VERSION "2027-draft-2026-10-23"

NS_ :

BS_:

BU_: BPS DEI External LVC MIKA MPPTInterface PDU Pedals VCU
VAL_TABLE_ EnableDisable 1 "Enabled" 0 "Disabled" ;
VAL_TABLE_ OnOff 1 "On" 0 "Off" ;
VAL_TABLE_ FaultState 1 "Fault" 0 "OK" ;
VAL_TABLE_ WarningState 1 "Warning" 0 "NoWarning" ;
VAL_TABLE_ DeviceStatus 2 "Waiting" 1 "Fault" 0 "OK" ;
VAL_TABLE_ Permission 1 "Allowed" 0 "NotAllowed" ;
VAL_TABLE_ Connection 1 "Connected" 0 "Disconnected" ;
VAL_TABLE_ Pressed 1 "Pressed" 0 "NotPressed" ;
VAL_TABLE_ Validity 1 "Valid" 0 "Invalid" ;
VAL_TABLE_ Watchdog 1 "TimedOut" 0 "Alive" ;
VAL_TABLE_ NormalAdvanced 1 "Advanced" 0 "Normal" ;
VAL_TABLE_ MotorCommandSource 1 "External" 0 "VCU" ;
VAL_TABLE_ Gear 3 "Invalid" 2 "Reverse" 1 "Forward" 0 "Neutral" ;
VAL_TABLE_ BPSFaultSummary 5 "SMBFault" 4 "PrechargeFault" 3 "ContactorRelayFault" 2 "EmergencyStop" 1 "SetpointFault" 0 "OK" ;
VAL_TABLE_ VCUState 7 "VehicleNotReady" 6 "Disabled" 5 "CruiseControl" 4 "Regen" 3 "ReverseDrive" 2 "NeutralDrive" 1 "ForwardDrive" 0 "Init" ;
VAL_TABLE_ ChargeState 2 "Charging" 1 "Standby" 0 "Disabled" ;
VAL_TABLE_ EVSEState 5 "F_EVSEFault" 4 "E_Fault" 3 "D_VentilationRequired" 2 "C_ChargingReady" 1 "B_Connected" 0 "A_Disconnected" ;
VAL_TABLE_ GPSAntennaState 3 "Unknown" 2 "ShortCircuit" 1 "OpenCircuit" 0 "OK" ;
VAL_TABLE_ GPSFix 2 "Fix3D" 1 "Fix2D" 0 "NoFix" ;
VAL_TABLE_ CellularTechnology 4 "Other" 3 "NB_IoT" 2 "LTE_M" 1 "LTE" 0 "None" ;
VAL_TABLE_ TPEEControlMode 2 "ConstantInputVoltage" 1 "PerturbAndObserve" 0 "Disabled" ;
VAL_TABLE_ TPEEOperatingMode 7 "Fault" 6 "MinimumInputVoltage" 5 "TemperatureDerating" 4 "ConstantOutputCurrent" 3 "ConstantOutputVoltage" 2 "MinimumInputCurrent" 1 "ConstantInputCurrent" 0 "ConstantInputVoltage" ;
VAL_TABLE_ TPEEFault 8 "Fault" 7 "PhaseOverCurrent" 6 "InputUnderCurrent" 5 "InputOverCurrent" 4 "OutputOverCurrent" 3 "OutputOverVoltage" 2 "InputOverVoltage" 1 "ConfigurationError" 0 "OK" ;
VAL_TABLE_ LWSCalibration 1 "Calibrated" 0 "NotCalibrated" ;
VAL_TABLE_ LWSTrim 1 "Trimmed" 0 "NotTrimmed" ;
VAL_TABLE_ LWSCommand 5 "ResetCalibration" 3 "SetAngleZero" ;
VAL_TABLE_ ElconControl 1 "Disable" 0 "Charge" ;
VAL_TABLE_ ElconMuxPage 5 "Page5" 4 "Page4" 3 "Page3" 2 "Page2" 1 "Page1" ;

BO_ 81 BPSCommand: 12 External
 SG_ Mode : 0|1@1+ (1,0) [0.0|1.0] "" Vector__XXX
 SG_ MPPTChargeScheme : 1|1@1+ (1,0) [0.0|1.0] "" Vector__XXX
 SG_ VoltageOverrideMask : 2|32@1+ (1,0) [0.0|4294967295.0] "" Vector__XXX
 SG_ TemperatureOverrideMask : 34|32@1+ (1,0) [0.0|4294967295.0] "" Vector__XXX

BO_ 82 PDUCommand: 1 External
 SG_ ChannelIndex : 0|4@1+ (1,0) [0|13] "" Vector__XXX
 SG_ Enable : 4|1@1+ (1,0) [0.0|1.0] "" Vector__XXX

BO_ 83 MotorControllerCommand: 1 External
 SG_ CommandSource : 0|1@1+ (1,0) [0.0|1.0] "" Vector__XXX

BO_ 84 SweepMPPTs: 0 External

BO_ 96 BPSStatus: 16 BPS
 SG_ FaultSummary : 0|3@1+ (1,0) [0.0|7.0] "" Vector__XXX
 SG_ FaultOverTemperature : 3|1@1+ (1,0) [0.0|1.0] "" Vector__XXX
 SG_ FaultOverVoltage : 4|1@1+ (1,0) [0.0|1.0] "" Vector__XXX
 SG_ FaultUnderVoltage : 5|1@1+ (1,0) [0.0|1.0] "" Vector__XXX
 SG_ FaultChargeOverCurrent : 6|1@1+ (1,0) [0.0|1.0] "" Vector__XXX
 SG_ FaultDischargeOverCurrent : 7|1@1+ (1,0) [0.0|1.0] "" Vector__XXX
 SG_ FaultHVPositiveContactorMismatch : 8|1@1+ (1,0) [0.0|1.0] "" Vector__XXX
 SG_ FaultMotorContactorMismatch : 9|1@1+ (1,0) [0.0|1.0] "" Vector__XXX
 SG_ FaultHVNegativeContactorMismatch : 10|1@1+ (1,0) [0.0|1.0] "" Vector__XXX
 SG_ FaultMainPrechargeRelayMismatch : 11|1@1+ (1,0) [0.0|1.0] "" Vector__XXX
 SG_ FaultMotorPrechargeRelayMismatch : 12|1@1+ (1,0) [0.0|1.0] "" Vector__XXX
 SG_ FaultDriverEstop : 13|1@1+ (1,0) [0.0|1.0] "" Vector__XXX
 SG_ FaultExternalEstop : 14|1@1+ (1,0) [0.0|1.0] "" Vector__XXX
 SG_ FaultBatteryEstop : 15|1@1+ (1,0) [0.0|1.0] "" Vector__XXX
 SG_ FaultChargerEstop : 16|1@1+ (1,0) [0.0|1.0] "" Vector__XXX
 SG_ FaultMainPrechargeTimeout : 17|1@1+ (1,0) [0.0|1.0] "" Vector__XXX
 SG_ FaultMotorPrechargeTimeout : 18|1@1+ (1,0) [0.0|1.0] "" Vector__XXX
 SG_ FaultMainVoltage : 19|1@1+ (1,0) [0.0|1.0] "" Vector__XXX
 SG_ FaultMotorVoltage : 20|1@1+ (1,0) [0.0|1.0] "" Vector__XXX
 SG_ FaultMainPrechargeVoltage : 21|1@1+ (1,0) [0.0|1.0] "" Vector__XXX
 SG_ FaultMotorPrechargeVoltage : 22|1@1+ (1,0) [0.0|1.0] "" Vector__XXX
 SG_ WarningSMBCommunication : 24|1@1+ (1,0) [0.0|1.0] "" Vector__XXX
 SG_ WarningUnderVoltage : 25|1@1+ (1,0) [0.0|1.0] "" Vector__XXX
 SG_ WarningOverVoltage : 26|1@1+ (1,0) [0.0|1.0] "" Vector__XXX
 SG_ WarningChargeOverTemperature : 27|1@1+ (1,0) [0.0|1.0] "" Vector__XXX
 SG_ WarningDischargeOverTemperature : 28|1@1+ (1,0) [0.0|1.0] "" Vector__XXX
 SG_ WarningBatteryFan1 : 29|1@1+ (1,0) [0.0|1.0] "" Vector__XXX
 SG_ WarningBatteryFan2 : 30|1@1+ (1,0) [0.0|1.0] "" Vector__XXX
 SG_ WarningBPSFan : 31|1@1+ (1,0) [0.0|1.0] "" Vector__XXX
 SG_ Status : 32|2@1+ (1,0) [0.0|3.0] "" Vector__XXX
 SG_ DriveOK : 34|1@1+ (1,0) [0.0|1.0] "" Vector__XXX
 SG_ ChargeOK : 35|1@1+ (1,0) [0.0|1.0] "" Vector__XXX
 SG_ MPPTSetMode : 36|2@1+ (1,0) [0.0|3.0] "" Vector__XXX
 SG_ ElconChargeOK : 38|1@1+ (1,0) [0.0|1.0] "" Vector__XXX
 SG_ RegenChargeOK : 39|1@1+ (1,0) [0.0|1.0] "" Vector__XXX
 SG_ HVPositiveContactor : 40|1@1+ (1,0) [0.0|1.0] "" Vector__XXX
 SG_ MotorContactor : 41|1@1+ (1,0) [0.0|1.0] "" Vector__XXX
 SG_ HVNegativeContactor : 42|1@1+ (1,0) [0.0|1.0] "" Vector__XXX
 SG_ MainPrechargeRelay : 43|1@1+ (1,0) [0.0|1.0] "" Vector__XXX
 SG_ MotorPrechargeRelay : 44|1@1+ (1,0) [0.0|1.0] "" Vector__XXX
 SG_ MPPTVoltageLimit : 48|16@1+ (0.05,0) [0|175] "V" Vector__XXX
 SG_ MPPTCurrentLimit : 64|16@1+ (0.01,0) [0|16.38] "A" Vector__XXX
 SG_ BatteryFanTach1 : 80|12@1+ (5,0) [0.0|20475.0] "rpm" Vector__XXX
 SG_ BatteryFanTach2 : 92|12@1+ (5,0) [0.0|20475.0] "rpm" Vector__XXX
 SG_ BPSFanTach : 104|12@1+ (5,0) [0.0|20475.0] "rpm" Vector__XXX

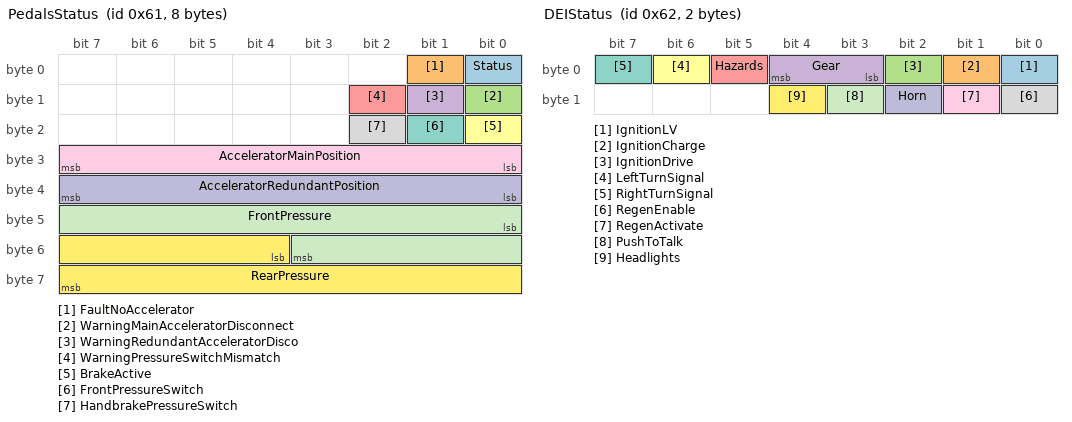
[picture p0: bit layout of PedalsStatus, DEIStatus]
BO_ 97 PedalsStatus: 8 Pedals
 SG_ Status : 0|1@1+ (1,0) [0.0|1.0] "" Vector__XXX
 SG_ FaultNoAccelerator : 1|1@1+ (1,0) [0.0|1.0] "" Vector__XXX
 SG_ WarningMainAcceleratorDisconnect : 8|1@1+ (1,0) [0.0|1.0] "" Vector__XXX
 SG_ WarningRedundantAcceleratorDisco : 9|1@1+ (1,0) [0.0|1.0] "" Vector__XXX
 SG_ WarningPressureSwitchMismatch : 10|1@1+ (1,0) [0.0|1.0] "" Vector__XXX
 SG_ BrakeActive : 16|1@1+ (1,0) [0.0|1.0] "" Vector__XXX
 SG_ FrontPressureSwitch : 17|1@1+ (1,0) [0.0|1.0] "" Vector__XXX
 SG_ HandbrakePressureSwitch : 18|1@1+ (1,0) [0.0|1.0] "" Vector__XXX
 SG_ AcceleratorMainPosition : 24|8@1+ (0.39215686274509803,0) [0|100] "%" Vector__XXX
 SG_ AcceleratorRedundantPosition : 32|8@1+ (0.39215686274509803,0) [0|100] "%" Vector__XXX
 SG_ FrontPressure : 40|12@1+ (1,0) [0|3000] "PSI" Vector__XXX
 SG_ RearPressure : 52|12@1+ (1,0) [0|3000] "PSI" Vector__XXX

BO_ 98 DEIStatus: 2 DEI
 SG_ IgnitionLV : 0|1@1+ (1,0) [0.0|1.0] "" Vector__XXX
 SG_ IgnitionCharge : 1|1@1+ (1,0) [0.0|1.0] "" Vector__XXX
 SG_ IgnitionDrive : 2|1@1+ (1,0) [0.0|1.0] "" Vector__XXX
 SG_ Gear : 3|2@1+ (1,0) [0.0|3.0] "" Vector__XXX
 SG_ Hazards : 5|1@1+ (1,0) [0.0|1.0] "" Vector__XXX
 SG_ LeftTurnSignal : 6|1@1+ (1,0) [0.0|1.0] "" Vector__XXX
 SG_ RightTurnSignal : 7|1@1+ (1,0) [0.0|1.0] "" Vector__XXX
 SG_ RegenEnable : 8|1@1+ (1,0) [0.0|1.0] "" Vector__XXX
 SG_ RegenActivate : 9|1@1+ (1,0) [0.0|1.0] "" Vector__XXX
 SG_ Horn : 10|1@1+ (1,0) [0.0|1.0] "" Vector__XXX
 SG_ PushToTalk : 11|1@1+ (1,0) [0.0|1.0] "" Vector__XXX
 SG_ Headlights : 12|1@1+ (1,0) [0.0|1.0] "" Vector__XXX

BO_ 99 VCUStatus: 7 VCU
 SG_ Status : 0|1@1+ (1,0) [0.0|1.0] "" Vector__XXX
 SG_ FaultMotor : 1|1@1+ (1,0) [0.0|1.0] "" Vector__XXX
 SG_ FaultBPS : 2|1@1+ (1,0) [0.0|1.0] "" Vector__XXX
 SG_ FaultPedals : 3|1@1+ (1,0) [0.0|1.0] "" Vector__XXX
 SG_ FaultMotorControllerWatchdog : 4|1@1+ (1,0) [0.0|1.0] "" Vector__XXX
 SG_ FaultBPSWatchdog : 5|1@1+ (1,0) [0.0|1.0] "" Vector__XXX
 SG_ FaultDriverInputWatchdog : 6|1@1+ (1,0) [0.0|1.0] "" Vector__XXX
 SG_ FaultPedalsWatchdog : 7|1@1+ (1,0) [0.0|1.0] "" Vector__XXX
 SG_ WarningTipping : 8|1@1+ (1,0) [0.0|1.0] "" Vector__XXX
 SG_ WarningDirectionChangeLockout : 9|1@1+ (1,0) [0.0|1.0] "" Vector__XXX
 SG_ WarningMotorControllerFan : 10|1@1+ (1,0) [0.0|1.0] "" Vector__XXX
 SG_ WarningMotorFan : 11|1@1+ (1,0) [0.0|1.0] "" Vector__XXX
 SG_ RegenEnabled : 16|1@1+ (1,0) [0.0|1.0] "" Vector__XXX
 SG_ State : 17|3@1+ (1,0) [0.0|7.0] "" Vector__XXX
 SG_ FSMBrake : 20|1@1+ (1,0) [0.0|1.0] "" Vector__XXX
 SG_ FSMBPSDriveOK : 21|1@1+ (1,0) [0.0|1.0] "" Vector__XXX
 SG_ FSMBPSRegenOK : 22|1@1+ (1,0) [0.0|1.0] "" Vector__XXX
 SG_ FSMDriverRegenEnable : 23|1@1+ (1,0) [0.0|1.0] "" Vector__XXX
 SG_ FSMDriverRegenRequest : 24|1@1+ (1,0) [0.0|1.0] "" Vector__XXX
 SG_ FSMGear : 25|2@1+ (1,0) [0.0|3.0] "" Vector__XXX
 SG_ MotorCommandSource : 27|1@1+ (1,0) [0.0|1.0] "" Vector__XXX
 SG_ MotorControllerFanTach : 32|12@1+ (5,0) [0.0|20475.0] "rpm" Vector__XXX
 SG_ MotorFanTach : 44|12@1+ (5,0) [0.0|20475.0] "rpm" Vector__XXX

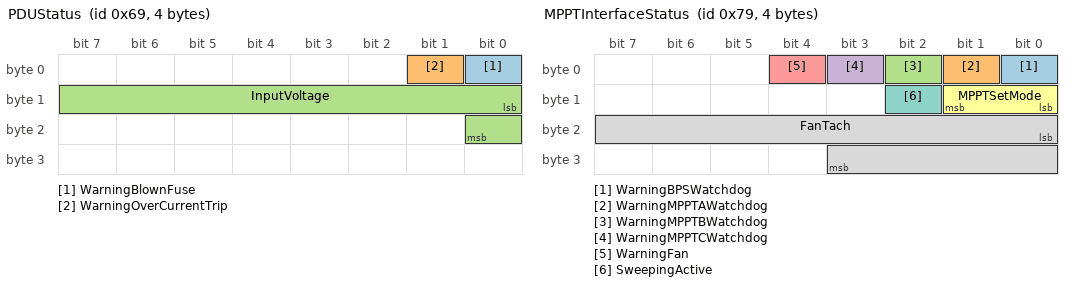
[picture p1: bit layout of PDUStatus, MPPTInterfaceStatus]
BO_ 105 PDUStatus: 4 PDU
 SG_ WarningBlownFuse : 0|1@1+ (1,0) [0.0|1.0] "" Vector__XXX
 SG_ WarningOverCurrentTrip : 1|1@1+ (1,0) [0.0|1.0] "" Vector__XXX
 SG_ InputVoltage : 8|9@1+ (0.05,0) [5|20] "V" Vector__XXX

BO_ 106 LVCStatus: 12 LVC
 SG_ WarningNoDCDCOutput : 0|1@1+ (1,0) [0.0|1.0] "" Vector__XXX
 SG_ WarningBPSOverCurrent : 1|1@1+ (1,0) [0.0|1.0] "" Vector__XXX
 SG_ WarningBPSBlownFuse : 2|1@1+ (1,0) [0.0|1.0] "" Vector__XXX
 SG_ DCDCEnabled : 8|1@1+ (1,0) [0.0|1.0] "" Vector__XXX
 SG_ DCDCVoltage : 16|9@1+ (0.05,0) [5|20] "V" Vector__XXX
 SG_ DCDCCurrent : 25|11@1+ (0.01,0) [0|20] "A" Vector__XXX
 SG_ LVBVoltage : 36|9@1+ (0.05,0) [5|20] "V" Vector__XXX
 SG_ LVBCurrent : 45|11@1+ (0.01,0) [0|20] "A" Vector__XXX
 SG_ PowerSupplyVoltage : 56|9@1+ (0.05,0) [5|20] "V" Vector__XXX
 SG_ TotalOutputCurrent : 65|11@1+ (0.01,0) [0|20] "A" Vector__XXX
 SG_ BPSLVCurrent : 76|11@1+ (0.01,0) [0|20] "A" Vector__XXX

BO_ 112 BPSPackData: 12 BPS
 SG_ CellSumVoltage : 0|12@1+ (0.05,0) [0.0|204.75] "V" Vector__XXX
 SG_ MainBatteryVoltage : 12|12@1+ (0.05,0) [0.0|204.75] "V" Vector__XXX
 SG_ MotorBatteryVoltage : 24|12@1+ (0.05,0) [0.0|204.75] "V" Vector__XXX
 SG_ MainVoltage : 36|12@1+ (0.05,0) [0.0|204.75] "V" Vector__XXX
 SG_ MotorVoltage : 48|12@1+ (0.05,0) [0.0|204.75] "V" Vector__XXX
 SG_ BatteryCurrent : 60|14@1+ (0.01,-50) [-50.0|113.83] "A" Vector__XXX

BO_ 113 BPSVoltageData: 64 BPS
 SG_ CellVoltage01 : 0|12@1+ (1,2000) [2000.0|6095.0] "mV" Vector__XXX
 SG_ CellVoltage02 : 12|12@1+ (1,2000) [2000.0|6095.0] "mV" Vector__XXX
 SG_ CellVoltage03 : 24|12@1+ (1,2000) [2000.0|6095.0] "mV" Vector__XXX
 SG_ CellVoltage04 : 36|12@1+ (1,2000) [2000.0|6095.0] "mV" Vector__XXX
 SG_ CellVoltage05 : 48|12@1+ (1,2000) [2000.0|6095.0] "mV" Vector__XXX
 SG_ CellVoltage06 : 60|12@1+ (1,2000) [2000.0|6095.0] "mV" Vector__XXX
 SG_ CellVoltage07 : 72|12@1+ (1,2000) [2000.0|6095.0] "mV" Vector__XXX
 SG_ CellVoltage08 : 84|12@1+ (1,2000) [2000.0|6095.0] "mV" Vector__XXX
 SG_ CellVoltage09 : 96|12@1+ (1,2000) [2000.0|6095.0] "mV" Vector__XXX
 SG_ CellVoltage10 : 108|12@1+ (1,2000) [2000.0|6095.0] "mV" Vector__XXX
 SG_ CellVoltage11 : 120|12@1+ (1,2000) [2000.0|6095.0] "mV" Vector__XXX
 SG_ CellVoltage12 : 132|12@1+ (1,2000) [2000.0|6095.0] "mV" Vector__XXX
 SG_ CellVoltage13 : 144|12@1+ (1,2000) [2000.0|6095.0] "mV" Vector__XXX
 SG_ CellVoltage14 : 156|12@1+ (1,2000) [2000.0|6095.0] "mV" Vector__XXX
 SG_ CellVoltage15 : 168|12@1+ (1,2000) [2000.0|6095.0] "mV" Vector__XXX
 SG_ CellVoltage16 : 180|12@1+ (1,2000) [2000.0|6095.0] "mV" Vector__XXX
 SG_ CellVoltage17 : 192|12@1+ (1,2000) [2000.0|6095.0] "mV" Vector__XXX
 SG_ CellVoltage18 : 204|12@1+ (1,2000) [2000.0|6095.0] "mV" Vector__XXX
 SG_ CellVoltage19 : 216|12@1+ (1,2000) [2000.0|6095.0] "mV" Vector__XXX
 SG_ CellVoltage20 : 228|12@1+ (1,2000) [2000.0|6095.0] "mV" Vector__XXX
 SG_ CellVoltage21 : 240|12@1+ (1,2000) [2000.0|6095.0] "mV" Vector__XXX
 SG_ CellVoltage22 : 252|12@1+ (1,2000) [2000.0|6095.0] "mV" Vector__XXX
 SG_ CellVoltage23 : 264|12@1+ (1,2000) [2000.0|6095.0] "mV" Vector__XXX
 SG_ CellVoltage24 : 276|12@1+ (1,2000) [2000.0|6095.0] "mV" Vector__XXX
 SG_ CellVoltage25 : 288|12@1+ (1,2000) [2000.0|6095.0] "mV" Vector__XXX
 SG_ CellVoltage26 : 300|12@1+ (1,2000) [2000.0|6095.0] "mV" Vector__XXX
 SG_ CellVoltage27 : 312|12@1+ (1,2000) [2000.0|6095.0] "mV" Vector__XXX
 SG_ CellVoltage28 : 324|12@1+ (1,2000) [2000.0|6095.0] "mV" Vector__XXX
 SG_ CellVoltage29 : 336|12@1+ (1,2000) [2000.0|6095.0] "mV" Vector__XXX
 SG_ CellVoltage30 : 348|12@1+ (1,2000) [2000.0|6095.0] "mV" Vector__XXX
 SG_ CellVoltage31 : 360|12@1+ (1,2000) [2000.0|6095.0] "mV" Vector__XXX
 SG_ CellVoltage32 : 372|12@1+ (1,2000) [2000.0|6095.0] "mV" Vector__XXX
 SG_ MinCellVoltage : 384|12@1+ (1,2000) [2000.0|6095.0] "mV" Vector__XXX
 SG_ MaxCellVoltage : 396|12@1+ (1,2000) [2000.0|6095.0] "mV" Vector__XXX

BO_ 114 BPSTemperatureData: 48 BPS
 SG_ CellTemperature01 : 0|11@1+ (0.05,0) [0.0|102.35] "degC" Vector__XXX
 SG_ CellTemperature02 : 11|11@1+ (0.05,0) [0.0|102.35] "degC" Vector__XXX
 SG_ CellTemperature03 : 22|11@1+ (0.05,0) [0.0|102.35] "degC" Vector__XXX
 SG_ CellTemperature04 : 33|11@1+ (0.05,0) [0.0|102.35] "degC" Vector__XXX
 SG_ CellTemperature05 : 44|11@1+ (0.05,0) [0.0|102.35] "degC" Vector__XXX
 SG_ CellTemperature06 : 55|11@1+ (0.05,0) [0.0|102.35] "degC" Vector__XXX
 SG_ CellTemperature07 : 66|11@1+ (0.05,0) [0.0|102.35] "degC" Vector__XXX
 SG_ CellTemperature08 : 77|11@1+ (0.05,0) [0.0|102.35] "degC" Vector__XXX
 SG_ CellTemperature09 : 88|11@1+ (0.05,0) [0.0|102.35] "degC" Vector__XXX
 SG_ CellTemperature10 : 99|11@1+ (0.05,0) [0.0|102.35] "degC" Vector__XXX
 SG_ CellTemperature11 : 110|11@1+ (0.05,0) [0.0|102.35] "degC" Vector__XXX
 SG_ CellTemperature12 : 121|11@1+ (0.05,0) [0.0|102.35] "degC" Vector__XXX
 SG_ CellTemperature13 : 132|11@1+ (0.05,0) [0.0|102.35] "degC" Vector__XXX
 SG_ CellTemperature14 : 143|11@1+ (0.05,0) [0.0|102.35] "degC" Vector__XXX
 SG_ CellTemperature15 : 154|11@1+ (0.05,0) [0.0|102.35] "degC" Vector__XXX
 SG_ CellTemperature16 : 165|11@1+ (0.05,0) [0.0|102.35] "degC" Vector__XXX
 SG_ CellTemperature17 : 176|11@1+ (0.05,0) [0.0|102.35] "degC" Vector__XXX
 SG_ CellTemperature18 : 187|11@1+ (0.05,0) [0.0|102.35] "degC" Vector__XXX
 SG_ CellTemperature19 : 198|11@1+ (0.05,0) [0.0|102.35] "degC" Vector__XXX
 SG_ CellTemperature20 : 209|11@1+ (0.05,0) [0.0|102.35] "degC" Vector__XXX
 SG_ CellTemperature21 : 220|11@1+ (0.05,0) [0.0|102.35] "degC" Vector__XXX
 SG_ CellTemperature22 : 231|11@1+ (0.05,0) [0.0|102.35] "degC" Vector__XXX
 SG_ CellTemperature23 : 242|11@1+ (0.05,0) [0.0|102.35] "degC" Vector__XXX
 SG_ CellTemperature24 : 253|11@1+ (0.05,0) [0.0|102.35] "degC" Vector__XXX
 SG_ CellTemperature25 : 264|11@1+ (0.05,0) [0.0|102.35] "degC" Vector__XXX
 SG_ CellTemperature26 : 275|11@1+ (0.05,0) [0.0|102.35] "degC" Vector__XXX
 SG_ CellTemperature27 : 286|11@1+ (0.05,0) [0.0|102.35] "degC" Vector__XXX
 SG_ CellTemperature28 : 297|11@1+ (0.05,0) [0.0|102.35] "degC" Vector__XXX
 SG_ CellTemperature29 : 308|11@1+ (0.05,0) [0.0|102.35] "degC" Vector__XXX
 SG_ CellTemperature30 : 319|11@1+ (0.05,0) [0.0|102.35] "degC" Vector__XXX
 SG_ CellTemperature31 : 330|11@1+ (0.05,0) [0.0|102.35] "degC" Vector__XXX
 SG_ CellTemperature32 : 341|11@1+ (0.05,0) [0.0|102.35] "degC" Vector__XXX
 SG_ MaxBatteryTemperature : 352|11@1+ (0.05,0) [0.0|102.35] "degC" Vector__XXX
 SG_ AverageBatteryTemperature : 363|11@1+ (0.05,0) [0.0|102.35] "degC" Vector__XXX

BO_ 115 SMDStatus: 0 BPS

BO_ 116 BPSCommandEcho: 12 BPS
 SG_ Mode : 0|1@1+ (1,0) [0.0|1.0] "" Vector__XXX
 SG_ MPPTChargeScheme : 1|1@1+ (1,0) [0.0|1.0] "" Vector__XXX
 SG_ VoltageOverrideMask : 2|32@1+ (1,0) [0.0|4294967295.0] "" Vector__XXX
 SG_ TemperatureOverrideMask : 34|32@1+ (1,0) [0.0|4294967295.0] "" Vector__XXX

BO_ 120 PDUData: 32 PDU
 SG_ ChannelBlownFuse1 : 0|1@1+ (1,0) [0.0|1.0] "" Vector__XXX
 SG_ ChannelOverCurrent1 : 1|1@1+ (1,0) [0.0|1.0] "" Vector__XXX
 SG_ ChannelBlownFuse2 : 2|1@1+ (1,0) [0.0|1.0] "" Vector__XXX
 SG_ ChannelOverCurrent2 : 3|1@1+ (1,0) [0.0|1.0] "" Vector__XXX
 SG_ ChannelBlownFuse3 : 4|1@1+ (1,0) [0.0|1.0] "" Vector__XXX
 SG_ ChannelOverCurrent3 : 5|1@1+ (1,0) [0.0|1.0] "" Vector__XXX
 SG_ ChannelBlownFuse4 : 6|1@1+ (1,0) [0.0|1.0] "" Vector__XXX
 SG_ ChannelOverCurrent4 : 7|1@1+ (1,0) [0.0|1.0] "" Vector__XXX
 SG_ ChannelBlownFuse5 : 8|1@1+ (1,0) [0.0|1.0] "" Vector__XXX
 SG_ ChannelOverCurrent5 : 9|1@1+ (1,0) [0.0|1.0] "" Vector__XXX
 SG_ ChannelBlownFuse6 : 10|1@1+ (1,0) [0.0|1.0] "" Vector__XXX
 SG_ ChannelOverCurrent6 : 11|1@1+ (1,0) [0.0|1.0] "" Vector__XXX
 SG_ ChannelBlownFuse7 : 12|1@1+ (1,0) [0.0|1.0] "" Vector__XXX
 SG_ ChannelOverCurrent7 : 13|1@1+ (1,0) [0.0|1.0] "" Vector__XXX
 SG_ ChannelBlownFuse8 : 14|1@1+ (1,0) [0.0|1.0] "" Vector__XXX
 SG_ ChannelOverCurrent8 : 15|1@1+ (1,0) [0.0|1.0] "" Vector__XXX
 SG_ ChannelBlownFuse9 : 16|1@1+ (1,0) [0.0|1.0] "" Vector__XXX
 SG_ ChannelOverCurrent9 : 17|1@1+ (1,0) [0.0|1.0] "" Vector__XXX
 SG_ ChannelBlownFuse10 : 18|1@1+ (1,0) [0.0|1.0] "" Vector__XXX
 SG_ ChannelOverCurrent10 : 19|1@1+ (1,0) [0.0|1.0] "" Vector__XXX
 SG_ ChannelBlownFuse11 : 20|1@1+ (1,0) [0.0|1.0] "" Vector__XXX
 SG_ ChannelOverCurrent11 : 21|1@1+ (1,0) [0.0|1.0] "" Vector__XXX
 SG_ ChannelBlownFuse12 : 22|1@1+ (1,0) [0.0|1.0] "" Vector__XXX
 SG_ ChannelOverCurrent12 : 23|1@1+ (1,0) [0.0|1.0] "" Vector__XXX
 SG_ ChannelBlownFuse13 : 24|1@1+ (1,0) [0.0|1.0] "" Vector__XXX
 SG_ ChannelOverCurrent13 : 25|1@1+ (1,0) [0.0|1.0] "" Vector__XXX
 SG_ ChannelBlownFuse14 : 26|1@1+ (1,0) [0.0|1.0] "" Vector__XXX
 SG_ ChannelOverCurrent14 : 27|1@1+ (1,0) [0.0|1.0] "" Vector__XXX
 SG_ ChannelEnabled1 : 32|1@1+ (1,0) [0.0|1.0] "" Vector__XXX
 SG_ ChannelEnabled2 : 33|1@1+ (1,0) [0.0|1.0] "" Vector__XXX
 SG_ ChannelEnabled3 : 34|1@1+ (1,0) [0.0|1.0] "" Vector__XXX
 SG_ ChannelEnabled4 : 35|1@1+ (1,0) [0.0|1.0] "" Vector__XXX
 SG_ ChannelEnabled5 : 36|1@1+ (1,0) [0.0|1.0] "" Vector__XXX
 SG_ ChannelEnabled6 : 37|1@1+ (1,0) [0.0|1.0] "" Vector__XXX
 SG_ ChannelEnabled7 : 38|1@1+ (1,0) [0.0|1.0] "" Vector__XXX
 SG_ ChannelEnabled8 : 39|1@1+ (1,0) [0.0|1.0] "" Vector__XXX
 SG_ ChannelEnabled9 : 40|1@1+ (1,0) [0.0|1.0] "" Vector__XXX
 SG_ ChannelEnabled10 : 41|1@1+ (1,0) [0.0|1.0] "" Vector__XXX
 SG_ ChannelEnabled11 : 42|1@1+ (1,0) [0.0|1.0] "" Vector__XXX
 SG_ ChannelEnabled12 : 43|1@1+ (1,0) [0.0|1.0] "" Vector__XXX
 SG_ ChannelEnabled13 : 44|1@1+ (1,0) [0.0|1.0] "" Vector__XXX
 SG_ ChannelEnabled14 : 45|1@1+ (1,0) [0.0|1.0] "" Vector__XXX
 SG_ ChannelCurrent1 : 48|11@1+ (0.01,0) [0|20] "A" Vector__XXX
 SG_ ChannelCurrent2 : 59|11@1+ (0.01,0) [0|20] "A" Vector__XXX
 SG_ ChannelCurrent3 : 70|11@1+ (0.01,0) [0|20] "A" Vector__XXX
 SG_ ChannelCurrent4 : 81|11@1+ (0.01,0) [0|20] "A" Vector__XXX
 SG_ ChannelCurrent5 : 92|11@1+ (0.01,0) [0|20] "A" Vector__XXX
 SG_ ChannelCurrent6 : 103|11@1+ (0.01,0) [0|20] "A" Vector__XXX
 SG_ ChannelCurrent7 : 114|11@1+ (0.01,0) [0|20] "A" Vector__XXX
 SG_ ChannelCurrent8 : 125|11@1+ (0.01,0) [0|20] "A" Vector__XXX
 SG_ ChannelCurrent9 : 136|11@1+ (0.01,0) [0|20] "A" Vector__XXX
 SG_ ChannelCurrent10 : 147|11@1+ (0.01,0) [0|20] "A" Vector__XXX
 SG_ ChannelCurrent11 : 158|11@1+ (0.01,0) [0|20] "A" Vector__XXX
 SG_ ChannelCurrent12 : 169|11@1+ (0.01,0) [0|20] "A" Vector__XXX
 SG_ ChannelCurrent13 : 180|11@1+ (0.01,0) [0|20] "A" Vector__XXX
 SG_ ChannelCurrent14 : 191|11@1+ (0.01,0) [0|20] "A" Vector__XXX
 SG_ TotalCurrent : 202|11@1+ (0.01,0) [0|20] "A" Vector__XXX

BO_ 121 MPPTInterfaceStatus: 4 MPPTInterface
 SG_ WarningBPSWatchdog : 0|1@1+ (1,0) [0.0|1.0] "" Vector__XXX
 SG_ WarningMPPTAWatchdog : 1|1@1+ (1,0) [0.0|1.0] "" Vector__XXX
 SG_ WarningMPPTBWatchdog : 2|1@1+ (1,0) [0.0|1.0] "" Vector__XXX
 SG_ WarningMPPTCWatchdog : 3|1@1+ (1,0) [0.0|1.0] "" Vector__XXX
 SG_ WarningFan : 4|1@1+ (1,0) [0.0|1.0] "" Vector__XXX
 SG_ MPPTSetMode : 8|2@1+ (1,0) [0.0|3.0] "" Vector__XXX
 SG_ SweepingActive : 10|1@1+ (1,0) [0.0|1.0] "" Vector__XXX
 SG_ FanTach : 16|12@1+ (5,0) [0.0|20475.0] "rpm" Vector__XXX

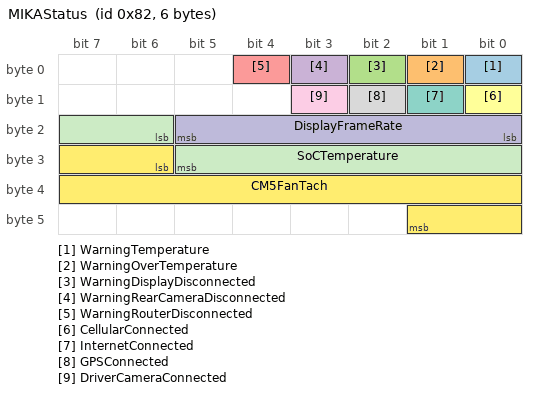
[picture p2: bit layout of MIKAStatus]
BO_ 130 MIKAStatus: 6 MIKA
 SG_ WarningTemperature : 0|1@1+ (1,0) [0.0|1.0] "" Vector__XXX
 SG_ WarningOverTemperature : 1|1@1+ (1,0) [0.0|1.0] "" Vector__XXX
 SG_ WarningDisplayDisconnected : 2|1@1+ (1,0) [0.0|1.0] "" Vector__XXX
 SG_ WarningRearCameraDisconnected : 3|1@1+ (1,0) [0.0|1.0] "" Vector__XXX
 SG_ WarningRouterDisconnected : 4|1@1+ (1,0) [0.0|1.0] "" Vector__XXX
 SG_ CellularConnected : 8|1@1+ (1,0) [0.0|1.0] "" Vector__XXX
 SG_ InternetConnected : 9|1@1+ (1,0) [0.0|1.0] "" Vector__XXX
 SG_ GPSConnected : 10|1@1+ (1,0) [0.0|1.0] "" Vector__XXX
 SG_ DriverCameraConnected : 11|1@1+ (1,0) [0.0|1.0] "" Vector__XXX
 SG_ DisplayFrameRate : 16|6@1+ (1,0) [0|60] "FPS" Vector__XXX
 SG_ SoCTemperature : 22|8@1+ (0.5,-20) [-20|85] "degC" Vector__XXX
 SG_ CM5FanTach : 30|12@1+ (5,0) [0|20475] "rpm" Vector__XXX

BO_ 117 BPSFaultSnapshot: 16 BPS
 SG_ FaultSummary : 0|3@1+ (1,0) [0.0|7.0] "" Vector__XXX
 SG_ FaultOverTemperature : 3|1@1+ (1,0) [0.0|1.0] "" Vector__XXX
 SG_ FaultOverVoltage : 4|1@1+ (1,0) [0.0|1.0] "" Vector__XXX
 SG_ FaultUnderVoltage : 5|1@1+ (1,0) [0.0|1.0] "" Vector__XXX
 SG_ FaultChargeOverCurrent : 6|1@1+ (1,0) [0.0|1.0] "" Vector__XXX
 SG_ FaultDischargeOverCurrent : 7|1@1+ (1,0) [0.0|1.0] "" Vector__XXX
 SG_ FaultHVPositiveContactorMismatch : 8|1@1+ (1,0) [0.0|1.0] "" Vector__XXX
 SG_ FaultMotorContactorMismatch : 9|1@1+ (1,0) [0.0|1.0] "" Vector__XXX
 SG_ FaultHVNegativeContactorMismatch : 10|1@1+ (1,0) [0.0|1.0] "" Vector__XXX
 SG_ FaultMainPrechargeRelayMismatch : 11|1@1+ (1,0) [0.0|1.0] "" Vector__XXX
 SG_ FaultMotorPrechargeRelayMismatch : 12|1@1+ (1,0) [0.0|1.0] "" Vector__XXX
 SG_ FaultDriverEstop : 13|1@1+ (1,0) [0.0|1.0] "" Vector__XXX
 SG_ FaultExternalEstop : 14|1@1+ (1,0) [0.0|1.0] "" Vector__XXX
 SG_ FaultBatteryEstop : 15|1@1+ (1,0) [0.0|1.0] "" Vector__XXX
 SG_ FaultChargerEstop : 16|1@1+ (1,0) [0.0|1.0] "" Vector__XXX
 SG_ FaultMainPrechargeTimeout : 17|1@1+ (1,0) [0.0|1.0] "" Vector__XXX
 SG_ FaultMotorPrechargeTimeout : 18|1@1+ (1,0) [0.0|1.0] "" Vector__XXX
 SG_ FaultMainVoltage : 19|1@1+ (1,0) [0.0|1.0] "" Vector__XXX
 SG_ FaultMotorVoltage : 20|1@1+ (1,0) [0.0|1.0] "" Vector__XXX
 SG_ FaultMainPrechargeVoltage : 21|1@1+ (1,0) [0.0|1.0] "" Vector__XXX
 SG_ FaultMotorPrechargeVoltage : 22|1@1+ (1,0) [0.0|1.0] "" Vector__XXX
 SG_ CurrentValid : 24|1@1+ (1,0) [0|1] "" Vector__XXX
 SG_ SnapshotId : 32|16@1+ (1,0) [0|65535] "" Vector__XXX
 SG_ CaptureTimeMs : 48|32@1+ (1,0) [0|4294967295] "ms" Vector__XXX
 SG_ CurrentSampleAgeMs : 80|16@1+ (1,0) [0|65535] "ms" Vector__XXX
 SG_ BatteryCurrent : 96|14@1+ (0.01,-50) [-50.0|113.83] "A" Vector__XXX

BO_ 118 BPSFaultVoltageSnapshot: 64 BPS
 SG_ SnapshotId : 0|16@1+ (1,0) [0|65535] "" Vector__XXX
 SG_ SampleValidMask : 16|32@1+ (1,0) [0|4294967295] "" Vector__XXX
 SG_ SampleAgeMs : 48|16@1+ (1,0) [0|65535] "ms" Vector__XXX
 SG_ CellVoltage01 : 64|12@1+ (1,2000) [2000.0|6095.0] "mV" Vector__XXX
 SG_ CellVoltage02 : 76|12@1+ (1,2000) [2000.0|6095.0] "mV" Vector__XXX
 SG_ CellVoltage03 : 88|12@1+ (1,2000) [2000.0|6095.0] "mV" Vector__XXX
 SG_ CellVoltage04 : 100|12@1+ (1,2000) [2000.0|6095.0] "mV" Vector__XXX
 SG_ CellVoltage05 : 112|12@1+ (1,2000) [2000.0|6095.0] "mV" Vector__XXX
 SG_ CellVoltage06 : 124|12@1+ (1,2000) [2000.0|6095.0] "mV" Vector__XXX
 SG_ CellVoltage07 : 136|12@1+ (1,2000) [2000.0|6095.0] "mV" Vector__XXX
 SG_ CellVoltage08 : 148|12@1+ (1,2000) [2000.0|6095.0] "mV" Vector__XXX
 SG_ CellVoltage09 : 160|12@1+ (1,2000) [2000.0|6095.0] "mV" Vector__XXX
 SG_ CellVoltage10 : 172|12@1+ (1,2000) [2000.0|6095.0] "mV" Vector__XXX
 SG_ CellVoltage11 : 184|12@1+ (1,2000) [2000.0|6095.0] "mV" Vector__XXX
 SG_ CellVoltage12 : 196|12@1+ (1,2000) [2000.0|6095.0] "mV" Vector__XXX
 SG_ CellVoltage13 : 208|12@1+ (1,2000) [2000.0|6095.0] "mV" Vector__XXX
 SG_ CellVoltage14 : 220|12@1+ (1,2000) [2000.0|6095.0] "mV" Vector__XXX
 SG_ CellVoltage15 : 232|12@1+ (1,2000) [2000.0|6095.0] "mV" Vector__XXX
 SG_ CellVoltage16 : 244|12@1+ (1,2000) [2000.0|6095.0] "mV" Vector__XXX
 SG_ CellVoltage17 : 256|12@1+ (1,2000) [2000.0|6095.0] "mV" Vector__XXX
 SG_ CellVoltage18 : 268|12@1+ (1,2000) [2000.0|6095.0] "mV" Vector__XXX
 SG_ CellVoltage19 : 280|12@1+ (1,2000) [2000.0|6095.0] "mV" Vector__XXX
 SG_ CellVoltage20 : 292|12@1+ (1,2000) [2000.0|6095.0] "mV" Vector__XXX
 SG_ CellVoltage21 : 304|12@1+ (1,2000) [2000.0|6095.0] "mV" Vector__XXX
 SG_ CellVoltage22 : 316|12@1+ (1,2000) [2000.0|6095.0] "mV" Vector__XXX
 SG_ CellVoltage23 : 328|12@1+ (1,2000) [2000.0|6095.0] "mV" Vector__XXX
 SG_ CellVoltage24 : 340|12@1+ (1,2000) [2000.0|6095.0] "mV" Vector__XXX
 SG_ CellVoltage25 : 352|12@1+ (1,2000) [2000.0|6095.0] "mV" Vector__XXX
 SG_ CellVoltage26 : 364|12@1+ (1,2000) [2000.0|6095.0] "mV" Vector__XXX
 SG_ CellVoltage27 : 376|12@1+ (1,2000) [2000.0|6095.0] "mV" Vector__XXX
 SG_ CellVoltage28 : 388|12@1+ (1,2000) [2000.0|6095.0] "mV" Vector__XXX
 SG_ CellVoltage29 : 400|12@1+ (1,2000) [2000.0|6095.0] "mV" Vector__XXX
 SG_ CellVoltage30 : 412|12@1+ (1,2000) [2000.0|6095.0] "mV" Vector__XXX
 SG_ CellVoltage31 : 424|12@1+ (1,2000) [2000.0|6095.0] "mV" Vector__XXX
 SG_ CellVoltage32 : 436|12@1+ (1,2000) [2000.0|6095.0] "mV" Vector__XXX

BO_ 119 BPSFaultTemperatureSnapshot: 64 BPS
 SG_ SnapshotId : 0|16@1+ (1,0) [0|65535] "" Vector__XXX
 SG_ SampleValidMask : 16|32@1+ (1,0) [0|4294967295] "" Vector__XXX
 SG_ SampleAgeMs : 48|16@1+ (1,0) [0|65535] "ms" Vector__XXX
 SG_ CellTemperature01 : 64|11@1+ (0.05,0) [0.0|102.35] "degC" Vector__XXX
 SG_ CellTemperature02 : 75|11@1+ (0.05,0) [0.0|102.35] "degC" Vector__XXX
 SG_ CellTemperature03 : 86|11@1+ (0.05,0) [0.0|102.35] "degC" Vector__XXX
 SG_ CellTemperature04 : 97|11@1+ (0.05,0) [0.0|102.35] "degC" Vector__XXX
 SG_ CellTemperature05 : 108|11@1+ (0.05,0) [0.0|102.35] "degC" Vector__XXX
 SG_ CellTemperature06 : 119|11@1+ (0.05,0) [0.0|102.35] "degC" Vector__XXX
 SG_ CellTemperature07 : 130|11@1+ (0.05,0) [0.0|102.35] "degC" Vector__XXX
 SG_ CellTemperature08 : 141|11@1+ (0.05,0) [0.0|102.35] "degC" Vector__XXX
 SG_ CellTemperature09 : 152|11@1+ (0.05,0) [0.0|102.35] "degC" Vector__XXX
 SG_ CellTemperature10 : 163|11@1+ (0.05,0) [0.0|102.35] "degC" Vector__XXX
 SG_ CellTemperature11 : 174|11@1+ (0.05,0) [0.0|102.35] "degC" Vector__XXX
 SG_ CellTemperature12 : 185|11@1+ (0.05,0) [0.0|102.35] "degC" Vector__XXX
 SG_ CellTemperature13 : 196|11@1+ (0.05,0) [0.0|102.35] "degC" Vector__XXX
 SG_ CellTemperature14 : 207|11@1+ (0.05,0) [0.0|102.35] "degC" Vector__XXX
 SG_ CellTemperature15 : 218|11@1+ (0.05,0) [0.0|102.35] "degC" Vector__XXX
 SG_ CellTemperature16 : 229|11@1+ (0.05,0) [0.0|102.35] "degC" Vector__XXX
 SG_ CellTemperature17 : 240|11@1+ (0.05,0) [0.0|102.35] "degC" Vector__XXX
 SG_ CellTemperature18 : 251|11@1+ (0.05,0) [0.0|102.35] "degC" Vector__XXX
 SG_ CellTemperature19 : 262|11@1+ (0.05,0) [0.0|102.35] "degC" Vector__XXX
 SG_ CellTemperature20 : 273|11@1+ (0.05,0) [0.0|102.35] "degC" Vector__XXX
 SG_ CellTemperature21 : 284|11@1+ (0.05,0) [0.0|102.35] "degC" Vector__XXX
 SG_ CellTemperature22 : 295|11@1+ (0.05,0) [0.0|102.35] "degC" Vector__XXX
 SG_ CellTemperature23 : 306|11@1+ (0.05,0) [0.0|102.35] "degC" Vector__XXX
 SG_ CellTemperature24 : 317|11@1+ (0.05,0) [0.0|102.35] "degC" Vector__XXX
 SG_ CellTemperature25 : 328|11@1+ (0.05,0) [0.0|102.35] "degC" Vector__XXX
 SG_ CellTemperature26 : 339|11@1+ (0.05,0) [0.0|102.35] "degC" Vector__XXX
 SG_ CellTemperature27 : 350|11@1+ (0.05,0) [0.0|102.35] "degC" Vector__XXX
 SG_ CellTemperature28 : 361|11@1+ (0.05,0) [0.0|102.35] "degC" Vector__XXX
 SG_ CellTemperature29 : 372|11@1+ (0.05,0) [0.0|102.35] "degC" Vector__XXX
 SG_ CellTemperature30 : 383|11@1+ (0.05,0) [0.0|102.35] "degC" Vector__XXX
 SG_ CellTemperature31 : 394|11@1+ (0.05,0) [0.0|102.35] "degC" Vector__XXX
 SG_ CellTemperature32 : 405|11@1+ (0.05,0) [0.0|102.35] "degC" Vector__XXX

CM_ BO_ 81 "2027 team-defined layout; physical values use the shared scaling conventions.";
CM_ SG_ 81 TemperatureOverrideMask "Bit 0 selects temperature 1; bit 31 selects temperature 32. Set bit requests the corresponding override.";
CM_ SG_ 81 VoltageOverrideMask "Bit 0 selects tap 1; bit 31 selects tap 32. Set bit requests the corresponding override.";
CM_ SG_ 81 MPPTChargeScheme "MPPTChargeScheme";
CM_ SG_ 81 Mode "Mode";
CM_ BO_ 82 "2027 team-defined layout; physical values use the shared scaling conventions.";
CM_ SG_ 82 Enable "Enable";
CM_ SG_ 82 ChannelIndex "ChannelIndex";
CM_ BO_ 83 "2027 team-defined layout; physical values use the shared scaling conventions.";
CM_ SG_ 83 CommandSource "CommandSource";
CM_ BO_ 84 "Defined empty trigger: request a sweep from all MPPTs through MPPTInterface. Zero-byte CAN-FD payload.";
CM_ BO_ 96 "BPS faults, warnings, state, contactors, control permissions, MPPT limits, and fan tachometers. Pack measurements are in BPSPackData (0x070). CAN-FD; no transmit period assigned yet.";
CM_ SG_ 96 BPSFanTach "BPSFanTach";
CM_ SG_ 96 BatteryFanTach2 "BatteryFan2Tach";
CM_ SG_ 96 BatteryFanTach1 "BatteryFan1Tach";
CM_ SG_ 96 MPPTCurrentLimit "MPPTCurrentLimit";
CM_ SG_ 96 MPPTVoltageLimit "MPPTVoltageLimit";
CM_ SG_ 96 MotorPrechargeRelay "MotorPrechargeRelay";
CM_ SG_ 96 MainPrechargeRelay "MainPrechargeRelay";
CM_ SG_ 96 HVNegativeContactor "HVNegativeContactor";
CM_ SG_ 96 MotorContactor "MotorContactor";
CM_ SG_ 96 HVPositiveContactor "HVPositiveContactor";
CM_ SG_ 96 RegenChargeOK "RegenChargeOK";
CM_ SG_ 96 ElconChargeOK "ElconChargeOK";
CM_ SG_ 96 MPPTSetMode "MPPTSetMode";
CM_ SG_ 96 ChargeOK "ChargeOK";
CM_ SG_ 96 DriveOK "DriveOK";
CM_ SG_ 96 Status "Status";
CM_ SG_ 96 WarningBPSFan "WarningBPSFan";
CM_ SG_ 96 WarningBatteryFan2 "WarningBatteryFan2";
CM_ SG_ 96 WarningBatteryFan1 "WarningBatteryFan1";
CM_ SG_ 96 WarningDischargeOverTemperature "WarningDischargeOverTemperature";
CM_ SG_ 96 WarningChargeOverTemperature "WarningChargeOverTemperature";
CM_ SG_ 96 WarningOverVoltage "WarningOverVoltage";
CM_ SG_ 96 WarningUnderVoltage "WarningUnderVoltage";
CM_ SG_ 96 WarningSMBCommunication "WarningSMBCommunication";
CM_ SG_ 96 FaultMotorPrechargeVoltage "FaultMotorPrechargeVoltage";
CM_ SG_ 96 FaultMainPrechargeVoltage "FaultMainPrechargeVoltage";
CM_ SG_ 96 FaultMotorVoltage "FaultMotorVoltage";
CM_ SG_ 96 FaultMainVoltage "FaultMainVoltage";
CM_ SG_ 96 FaultMotorPrechargeTimeout "FaultMotorPrechargeTimeout";
CM_ SG_ 96 FaultMainPrechargeTimeout "FaultMainPrechargeTimeout";
CM_ SG_ 96 FaultChargerEstop "FaultChargerEstop";
CM_ SG_ 96 FaultBatteryEstop "FaultBatteryEstop";
CM_ SG_ 96 FaultExternalEstop "FaultExternalEstop";
CM_ SG_ 96 FaultDriverEstop "FaultDriverEstop";
CM_ SG_ 96 FaultMotorPrechargeRelayMismatch "FaultMotorPrechargeRelayMismatch";
CM_ SG_ 96 FaultMainPrechargeRelayMismatch "FaultMainPrechargeRelayMismatch";
CM_ SG_ 96 FaultHVNegativeContactorMismatch "FaultHVNegativeContactorMismatch";
CM_ SG_ 96 FaultMotorContactorMismatch "FaultMotorContactorMismatch";
CM_ SG_ 96 FaultHVPositiveContactorMismatch "FaultHVPositiveContactorMismatch";
CM_ SG_ 96 FaultDischargeOverCurrent "FaultDischargeOverCurrent";
CM_ SG_ 96 FaultChargeOverCurrent "FaultChargeOverCurrent";
CM_ SG_ 96 FaultUnderVoltage "FaultUnderVoltage";
CM_ SG_ 96 FaultOverVoltage "FaultOverVoltage";
CM_ SG_ 96 FaultOverTemperature "FaultOverTemperature";
CM_ SG_ 96 FaultSummary "FaultSummary";
CM_ BO_ 97 "2027 team-defined layout; physical values use the shared scaling conventions.";
CM_ SG_ 97 RearPressure "RearPressure";
CM_ SG_ 97 FrontPressure "FrontPressure";
CM_ SG_ 97 AcceleratorRedundantPosition "AcceleratorRedundantPosition";
CM_ SG_ 97 AcceleratorMainPosition "AcceleratorMainPosition";
CM_ SG_ 97 HandbrakePressureSwitch "HandbrakePressureSwitch";
CM_ SG_ 97 FrontPressureSwitch "FrontPressureSwitch";
CM_ SG_ 97 BrakeActive "BrakeActive";
CM_ SG_ 97 WarningPressureSwitchMismatch "WarningPressureSwitchMismatch";
CM_ SG_ 97 WarningRedundantAcceleratorDisco "WarningRedundantAcceleratorDisconnected";
CM_ SG_ 97 WarningMainAcceleratorDisconnect "WarningMainAcceleratorDisconnected";
CM_ SG_ 97 FaultNoAccelerator "FaultNoAccelerator";
CM_ SG_ 97 Status "Status";
CM_ BO_ 98 "2027 team-defined layout; physical values use the shared scaling conventions.";
CM_ SG_ 98 Headlights "Headlights";
CM_ SG_ 98 PushToTalk "PushToTalk";
CM_ SG_ 98 Horn "Horn";
CM_ SG_ 98 RegenActivate "RegenActivate";
CM_ SG_ 98 RegenEnable "RegenEnable";
CM_ SG_ 98 RightTurnSignal "RightTurnSignal";
CM_ SG_ 98 LeftTurnSignal "LeftTurnSignal";
CM_ SG_ 98 Hazards "Hazards";
CM_ SG_ 98 Gear "Gear";
CM_ SG_ 98 IgnitionDrive "IgnitionDrive";
CM_ SG_ 98 IgnitionCharge "IgnitionCharge";
CM_ SG_ 98 IgnitionLV "IgnitionLV";
CM_ BO_ 99 "2027 team-defined layout; physical values use the shared scaling conventions.";
CM_ SG_ 99 MotorFanTach "MotorFanTach";
CM_ SG_ 99 MotorControllerFanTach "MotorControllerFanTach";
CM_ SG_ 99 MotorCommandSource "MotorCommandSource";
CM_ SG_ 99 FSMGear "FSMGear";
CM_ SG_ 99 FSMDriverRegenRequest "FSMDriverRegenRequest";
CM_ SG_ 99 FSMDriverRegenEnable "FSMDriverRegenEnable";
CM_ SG_ 99 FSMBPSRegenOK "FSMBPSRegenOK";
CM_ SG_ 99 FSMBPSDriveOK "FSMBPSDriveOK";
CM_ SG_ 99 FSMBrake "FSMBrake";
CM_ SG_ 99 State "State";
CM_ SG_ 99 RegenEnabled "RegenEnabled";
CM_ SG_ 99 WarningMotorFan "WarningMotorFan";
CM_ SG_ 99 WarningMotorControllerFan "WarningMotorControllerFan";
CM_ SG_ 99 WarningDirectionChangeLockout "WarningDirectionChangeLockout";
CM_ SG_ 99 WarningTipping "WarningTipping";
CM_ SG_ 99 FaultPedalsWatchdog "FaultPedalsWatchdog";
CM_ SG_ 99 FaultDriverInputWatchdog "FaultDriverInputWatchdog";
CM_ SG_ 99 FaultBPSWatchdog "FaultBPSWatchdog";
CM_ SG_ 99 FaultMotorControllerWatchdog "FaultMotorControllerWatchdog";
CM_ SG_ 99 FaultPedals "FaultPedals";
CM_ SG_ 99 FaultBPS "FaultBPS";
CM_ SG_ 99 FaultMotor "FaultMotor";
CM_ SG_ 99 Status "Status";
CM_ BO_ 105 "2027 team-defined layout; physical values use the shared scaling conventions.";
CM_ SG_ 105 InputVoltage "InputVoltage";
CM_ SG_ 105 WarningOverCurrentTrip "WarningOverCurrentTrip";
CM_ SG_ 105 WarningBlownFuse "WarningBlownFuse";
CM_ BO_ 106 "2027 team-defined layout; physical values use the shared scaling conventions.";
CM_ SG_ 106 BPSLVCurrent "BPSLVCurrent";
CM_ SG_ 106 TotalOutputCurrent "TotalOutputCurrent";
CM_ SG_ 106 PowerSupplyVoltage "PowerSupplyVoltage";
CM_ SG_ 106 LVBCurrent "LVBCurrent";
CM_ SG_ 106 LVBVoltage "LVBVoltage";
CM_ SG_ 106 DCDCCurrent "DCDCCurrent";
CM_ SG_ 106 DCDCVoltage "DCDCVoltage";
CM_ SG_ 106 DCDCEnabled "DCDCEnabled";
CM_ SG_ 106 WarningBPSBlownFuse "WarningBPSBlownFuse";
CM_ SG_ 106 WarningBPSOverCurrent "WarningBPSOverCurrent";
CM_ SG_ 106 WarningNoDCDCOutput "WarningNoDCDCOutput";
CM_ BO_ 112 "BPS pack electrical measurements: cell-sum and main/motor battery and precharge voltages, then battery current. Cell-voltage extrema are in BPSVoltageData; temperature summaries are in BPSTemperatureData. Signal encodings unchanged; no transmit period assigned yet.";
CM_ SG_ 112 BatteryCurrent "BatteryCurrent";
CM_ SG_ 112 MotorVoltage "MotorVoltage";
CM_ SG_ 112 MainVoltage "MainVoltage";
CM_ SG_ 112 MotorBatteryVoltage "MotorBatteryVoltage";
CM_ SG_ 112 MainBatteryVoltage "MainBatteryVoltage";
CM_ SG_ 112 CellSumVoltage "Sum of the 32 cell-tap voltages, independent of precharge measurements. Bulk voltage encoding: unsigned 12 bits, 0.05 V/bit, offset 0 V.";
CM_ BO_ 113 "BPS individual cell voltages followed by minimum/maximum cell voltage; unchanged physical encodings.";
CM_ SG_ 113 MaxCellVoltage "MaxCellVoltage";
CM_ SG_ 113 MinCellVoltage "MinCellVoltage";
CM_ SG_ 113 CellVoltage32 "CellVoltage32";
CM_ SG_ 113 CellVoltage31 "CellVoltage31";
CM_ SG_ 113 CellVoltage30 "CellVoltage30";
CM_ SG_ 113 CellVoltage29 "CellVoltage29";
CM_ SG_ 113 CellVoltage28 "CellVoltage28";
CM_ SG_ 113 CellVoltage27 "CellVoltage27";
CM_ SG_ 113 CellVoltage26 "CellVoltage26";
CM_ SG_ 113 CellVoltage25 "CellVoltage25";
CM_ SG_ 113 CellVoltage24 "CellVoltage24";
CM_ SG_ 113 CellVoltage23 "CellVoltage23";
CM_ SG_ 113 CellVoltage22 "CellVoltage22";
CM_ SG_ 113 CellVoltage21 "CellVoltage21";
CM_ SG_ 113 CellVoltage20 "CellVoltage20";
CM_ SG_ 113 CellVoltage19 "CellVoltage19";
CM_ SG_ 113 CellVoltage18 "CellVoltage18";
CM_ SG_ 113 CellVoltage17 "CellVoltage17";
CM_ SG_ 113 CellVoltage16 "CellVoltage16";
CM_ SG_ 113 CellVoltage15 "CellVoltage15";
CM_ SG_ 113 CellVoltage14 "CellVoltage14";
CM_ SG_ 113 CellVoltage13 "CellVoltage13";
CM_ SG_ 113 CellVoltage12 "CellVoltage12";
CM_ SG_ 113 CellVoltage11 "CellVoltage11";
CM_ SG_ 113 CellVoltage10 "CellVoltage10";
CM_ SG_ 113 CellVoltage09 "CellVoltage09";
CM_ SG_ 113 CellVoltage08 "CellVoltage08";
CM_ SG_ 113 CellVoltage07 "CellVoltage07";
CM_ SG_ 113 CellVoltage06 "CellVoltage06";
CM_ SG_ 113 CellVoltage05 "CellVoltage05";
CM_ SG_ 113 CellVoltage04 "CellVoltage04";
CM_ SG_ 113 CellVoltage03 "CellVoltage03";
CM_ SG_ 113 CellVoltage02 "CellVoltage02";
CM_ SG_ 113 CellVoltage01 "CellVoltage01";
CM_ BO_ 114 "BPS individual cell temperatures followed by maximum/average battery temperature; unchanged physical encodings.";
CM_ SG_ 114 AverageBatteryTemperature "AverageBatteryTemperature";
CM_ SG_ 114 MaxBatteryTemperature "MaxBatteryTemperature";
CM_ SG_ 114 CellTemperature32 "CellTemperature32";
CM_ SG_ 114 CellTemperature31 "CellTemperature31";
CM_ SG_ 114 CellTemperature30 "CellTemperature30";
CM_ SG_ 114 CellTemperature29 "CellTemperature29";
CM_ SG_ 114 CellTemperature28 "CellTemperature28";
CM_ SG_ 114 CellTemperature27 "CellTemperature27";
CM_ SG_ 114 CellTemperature26 "CellTemperature26";
CM_ SG_ 114 CellTemperature25 "CellTemperature25";
CM_ SG_ 114 CellTemperature24 "CellTemperature24";
CM_ SG_ 114 CellTemperature23 "CellTemperature23";
CM_ SG_ 114 CellTemperature22 "CellTemperature22";
CM_ SG_ 114 CellTemperature21 "CellTemperature21";
CM_ SG_ 114 CellTemperature20 "CellTemperature20";
CM_ SG_ 114 CellTemperature19 "CellTemperature19";
CM_ SG_ 114 CellTemperature18 "CellTemperature18";
CM_ SG_ 114 CellTemperature17 "CellTemperature17";
CM_ SG_ 114 CellTemperature16 "CellTemperature16";
CM_ SG_ 114 CellTemperature15 "CellTemperature15";
CM_ SG_ 114 CellTemperature14 "CellTemperature14";
CM_ SG_ 114 CellTemperature13 "CellTemperature13";
CM_ SG_ 114 CellTemperature12 "CellTemperature12";
CM_ SG_ 114 CellTemperature11 "CellTemperature11";
CM_ SG_ 114 CellTemperature10 "CellTemperature10";
CM_ SG_ 114 CellTemperature09 "CellTemperature09";
CM_ SG_ 114 CellTemperature08 "CellTemperature08";
CM_ SG_ 114 CellTemperature07 "CellTemperature07";
CM_ SG_ 114 CellTemperature06 "CellTemperature06";
CM_ SG_ 114 CellTemperature05 "CellTemperature05";
CM_ SG_ 114 CellTemperature04 "CellTemperature04";
CM_ SG_ 114 CellTemperature03 "CellTemperature03";
CM_ SG_ 114 CellTemperature02 "CellTemperature02";
CM_ SG_ 114 CellTemperature01 "CellTemperature01";
CM_ BO_ 115 "PLACEHOLDER: signals and payload length are not defined; zero DLC is a drafting marker, not an approved transmit layout. Four SMB status bitmaps: widths and bit definitions pending.";
CM_ BO_ 116 "Cyclic BPS report mirroring the BPSCommand payload: Mode, MPPTChargeScheme, VoltageOverrideMask, and TemperatureOverrideMask. Reports command values held by BPS; does not imply successful application or act as a per-request acknowledgement. Cyclic report every 1000 ms.";
CM_ SG_ 116 TemperatureOverrideMask "Bit 0 selects temperature 1; bit 31 selects temperature 32. Set bit requests the corresponding override.";
CM_ SG_ 116 VoltageOverrideMask "Bit 0 selects tap 1; bit 31 selects tap 32. Set bit requests the corresponding override.";
CM_ SG_ 116 MPPTChargeScheme "MPPTChargeScheme";
CM_ SG_ 116 Mode "Mode";
CM_ BO_ 120 "2027 team-defined layout; physical values use the shared scaling conventions.";
CM_ SG_ 120 TotalCurrent "TotalCurrent";
CM_ SG_ 120 ChannelCurrent14 "Channel14Current";
CM_ SG_ 120 ChannelCurrent13 "Channel13Current";
CM_ SG_ 120 ChannelCurrent12 "Channel12Current";
CM_ SG_ 120 ChannelCurrent11 "Channel11Current";
CM_ SG_ 120 ChannelCurrent10 "Channel10Current";
CM_ SG_ 120 ChannelCurrent9 "Channel09Current";
CM_ SG_ 120 ChannelCurrent8 "Channel08Current";
CM_ SG_ 120 ChannelCurrent7 "Channel07Current";
CM_ SG_ 120 ChannelCurrent6 "Channel06Current";
CM_ SG_ 120 ChannelCurrent5 "Channel05Current";
CM_ SG_ 120 ChannelCurrent4 "Channel04Current";
CM_ SG_ 120 ChannelCurrent3 "Channel03Current";
CM_ SG_ 120 ChannelCurrent2 "Channel02Current";
CM_ SG_ 120 ChannelCurrent1 "Channel01Current";
CM_ SG_ 120 ChannelEnabled14 "Channel14Enabled";
CM_ SG_ 120 ChannelEnabled13 "Channel13Enabled";
CM_ SG_ 120 ChannelEnabled12 "Channel12Enabled";
CM_ SG_ 120 ChannelEnabled11 "Channel11Enabled";
CM_ SG_ 120 ChannelEnabled10 "Channel10Enabled";
CM_ SG_ 120 ChannelEnabled9 "Channel09Enabled";
CM_ SG_ 120 ChannelEnabled8 "Channel08Enabled";
CM_ SG_ 120 ChannelEnabled7 "Channel07Enabled";
CM_ SG_ 120 ChannelEnabled6 "Channel06Enabled";
CM_ SG_ 120 ChannelEnabled5 "Channel05Enabled";
CM_ SG_ 120 ChannelEnabled4 "Channel04Enabled";
CM_ SG_ 120 ChannelEnabled3 "Channel03Enabled";
CM_ SG_ 120 ChannelEnabled2 "Channel02Enabled";
CM_ SG_ 120 ChannelEnabled1 "Channel01Enabled";
CM_ SG_ 120 ChannelOverCurrent14 "Channel14OverCurrent";
CM_ SG_ 120 ChannelBlownFuse14 "Channel14BlownFuse";
CM_ SG_ 120 ChannelOverCurrent13 "Channel13OverCurrent";
CM_ SG_ 120 ChannelBlownFuse13 "Channel13BlownFuse";
CM_ SG_ 120 ChannelOverCurrent12 "Channel12OverCurrent";
CM_ SG_ 120 ChannelBlownFuse12 "Channel12BlownFuse";
CM_ SG_ 120 ChannelOverCurrent11 "Channel11OverCurrent";
CM_ SG_ 120 ChannelBlownFuse11 "Channel11BlownFuse";
CM_ SG_ 120 ChannelOverCurrent10 "Channel10OverCurrent";
CM_ SG_ 120 ChannelBlownFuse10 "Channel10BlownFuse";
CM_ SG_ 120 ChannelOverCurrent9 "Channel09OverCurrent";
CM_ SG_ 120 ChannelBlownFuse9 "Channel09BlownFuse";
CM_ SG_ 120 ChannelOverCurrent8 "Channel08OverCurrent";
CM_ SG_ 120 ChannelBlownFuse8 "Channel08BlownFuse";
CM_ SG_ 120 ChannelOverCurrent7 "Channel07OverCurrent";
CM_ SG_ 120 ChannelBlownFuse7 "Channel07BlownFuse";
CM_ SG_ 120 ChannelOverCurrent6 "Channel06OverCurrent";
CM_ SG_ 120 ChannelBlownFuse6 "Channel06BlownFuse";
CM_ SG_ 120 ChannelOverCurrent5 "Channel05OverCurrent";
CM_ SG_ 120 ChannelBlownFuse5 "Channel05BlownFuse";
CM_ SG_ 120 ChannelOverCurrent4 "Channel04OverCurrent";
CM_ SG_ 120 ChannelBlownFuse4 "Channel04BlownFuse";
CM_ SG_ 120 ChannelOverCurrent3 "Channel03OverCurrent";
CM_ SG_ 120 ChannelBlownFuse3 "Channel03BlownFuse";
CM_ SG_ 120 ChannelOverCurrent2 "Channel02OverCurrent";
CM_ SG_ 120 ChannelBlownFuse2 "Channel02BlownFuse";
CM_ SG_ 120 ChannelOverCurrent1 "Channel01OverCurrent";
CM_ SG_ 120 ChannelBlownFuse1 "Channel01BlownFuse";
CM_ BO_ 121 "2027 team-defined layout; physical values use the shared scaling conventions.";
CM_ SG_ 121 FanTach "FanTach";
CM_ SG_ 121 SweepingActive "SweepingActive";
CM_ SG_ 121 MPPTSetMode "MPPTSetMode";
CM_ SG_ 121 WarningFan "WarningFan";
CM_ SG_ 121 WarningMPPTCWatchdog "WarningMPPTCWatchdog";
CM_ SG_ 121 WarningMPPTBWatchdog "WarningMPPTBWatchdog";
CM_ SG_ 121 WarningMPPTAWatchdog "WarningMPPTAWatchdog";
CM_ SG_ 121 WarningBPSWatchdog "WarningBPSWatchdog";
CM_ BO_ 130 "HMI and CM5 status from MIKA (combined HMI and telemetry board). Application ID 0x082 and signal layout retained.";
CM_ SG_ 130 CM5FanTach "CM5 cooling fan tachometer: unsigned 12 bits, 5 rpm/bit, offset 0 rpm.";
CM_ SG_ 130 SoCTemperature "User-approved explicit exception: uint8, 0.5 degC/bit, -20 degC offset.";
CM_ SG_ 130 DisplayFrameRate "DisplayFrameRate";
CM_ SG_ 130 DriverCameraConnected "Driver camera connection state: 0 disconnected, 1 connected.";
CM_ SG_ 130 GPSConnected "GPSConnected";
CM_ SG_ 130 InternetConnected "InternetConnected";
CM_ SG_ 130 CellularConnected "CellularConnected";
CM_ SG_ 130 WarningRouterDisconnected "WarningRouterDisconnected";
CM_ SG_ 130 WarningRearCameraDisconnected "Rear camera disconnected warning; the driver camera has a separate connected bit.";
CM_ SG_ 130 WarningDisplayDisconnected "WarningDisplayDisconnected";
CM_ SG_ 130 WarningOverTemperature "WarningOverTemperature";
CM_ SG_ 130 WarningTemperature "WarningTemperature";
CM_ BO_ 117 "Latch once when BPS transitions from no active faults to any active fault, before opening contactors where possible. Send immediately, then every 1000 ms only while any BPS fault remains active. All three frames reuse the same frozen SnapshotId; never replace captured samples with post-trip zeros. Rearm after all faults clear. SnapshotId is a wrapping 16-bit sequence within a boot. Fault bits record the first fault state. BatteryCurrent preserves the live message scaling. CurrentSampleAgeMs describes sampling latency; this is not a guaranteed instantaneous peak measurement.";
CM_ SG_ 117 BatteryCurrent "BatteryCurrent";
CM_ SG_ 117 CurrentSampleAgeMs "Age of last valid current sample at capture; saturates at 65535 ms.";
CM_ SG_ 117 CaptureTimeMs "BPS monotonic uptime at fault detection, wraps at 2^32 ms; independent of legacy TimestampSync ticks.";
CM_ SG_ 117 SnapshotId "Shared snapshot sequence; resets on BPS reboot.";
CM_ SG_ 117 CurrentValid "1 only if BatteryCurrent was sampled successfully before capture; otherwise ignore BatteryCurrent and CurrentSampleAgeMs.";
CM_ SG_ 117 FaultMotorPrechargeVoltage "FaultMotorPrechargeVoltage";
CM_ SG_ 117 FaultMainPrechargeVoltage "FaultMainPrechargeVoltage";
CM_ SG_ 117 FaultMotorVoltage "FaultMotorVoltage";
CM_ SG_ 117 FaultMainVoltage "FaultMainVoltage";
CM_ SG_ 117 FaultMotorPrechargeTimeout "FaultMotorPrechargeTimeout";
CM_ SG_ 117 FaultMainPrechargeTimeout "FaultMainPrechargeTimeout";
CM_ SG_ 117 FaultChargerEstop "FaultChargerEstop";
CM_ SG_ 117 FaultBatteryEstop "FaultBatteryEstop";
CM_ SG_ 117 FaultExternalEstop "FaultExternalEstop";
CM_ SG_ 117 FaultDriverEstop "FaultDriverEstop";
CM_ SG_ 117 FaultMotorPrechargeRelayMismatch "FaultMotorPrechargeRelayMismatch";
CM_ SG_ 117 FaultMainPrechargeRelayMismatch "FaultMainPrechargeRelayMismatch";
CM_ SG_ 117 FaultHVNegativeContactorMismatch "FaultHVNegativeContactorMismatch";
CM_ SG_ 117 FaultMotorContactorMismatch "FaultMotorContactorMismatch";
CM_ SG_ 117 FaultHVPositiveContactorMismatch "FaultHVPositiveContactorMismatch";
CM_ SG_ 117 FaultDischargeOverCurrent "FaultDischargeOverCurrent";
CM_ SG_ 117 FaultChargeOverCurrent "FaultChargeOverCurrent";
CM_ SG_ 117 FaultUnderVoltage "FaultUnderVoltage";
CM_ SG_ 117 FaultOverVoltage "FaultOverVoltage";
CM_ SG_ 117 FaultOverTemperature "FaultOverTemperature";
CM_ SG_ 117 FaultSummary "FaultSummary";
CM_ BO_ 118 "Latch once when BPS transitions from no active faults to any active fault, before opening contactors where possible. Send immediately, then every 1000 ms only while any BPS fault remains active. All three frames reuse the same frozen SnapshotId; never replace captured samples with post-trip zeros. Rearm after all faults clear. SnapshotId is a wrapping 16-bit sequence within a boot. The last completed scan available at fault detection is frozen, not acquired after shutdown. Scaling and offsets match BPSVoltageData.";
CM_ SG_ 118 CellVoltage32 "CellVoltage32";
CM_ SG_ 118 CellVoltage31 "CellVoltage31";
CM_ SG_ 118 CellVoltage30 "CellVoltage30";
CM_ SG_ 118 CellVoltage29 "CellVoltage29";
CM_ SG_ 118 CellVoltage28 "CellVoltage28";
CM_ SG_ 118 CellVoltage27 "CellVoltage27";
CM_ SG_ 118 CellVoltage26 "CellVoltage26";
CM_ SG_ 118 CellVoltage25 "CellVoltage25";
CM_ SG_ 118 CellVoltage24 "CellVoltage24";
CM_ SG_ 118 CellVoltage23 "CellVoltage23";
CM_ SG_ 118 CellVoltage22 "CellVoltage22";
CM_ SG_ 118 CellVoltage21 "CellVoltage21";
CM_ SG_ 118 CellVoltage20 "CellVoltage20";
CM_ SG_ 118 CellVoltage19 "CellVoltage19";
CM_ SG_ 118 CellVoltage18 "CellVoltage18";
CM_ SG_ 118 CellVoltage17 "CellVoltage17";
CM_ SG_ 118 CellVoltage16 "CellVoltage16";
CM_ SG_ 118 CellVoltage15 "CellVoltage15";
CM_ SG_ 118 CellVoltage14 "CellVoltage14";
CM_ SG_ 118 CellVoltage13 "CellVoltage13";
CM_ SG_ 118 CellVoltage12 "CellVoltage12";
CM_ SG_ 118 CellVoltage11 "CellVoltage11";
CM_ SG_ 118 CellVoltage10 "CellVoltage10";
CM_ SG_ 118 CellVoltage09 "CellVoltage09";
CM_ SG_ 118 CellVoltage08 "CellVoltage08";
CM_ SG_ 118 CellVoltage07 "CellVoltage07";
CM_ SG_ 118 CellVoltage06 "CellVoltage06";
CM_ SG_ 118 CellVoltage05 "CellVoltage05";
CM_ SG_ 118 CellVoltage04 "CellVoltage04";
CM_ SG_ 118 CellVoltage03 "CellVoltage03";
CM_ SG_ 118 CellVoltage02 "CellVoltage02";
CM_ SG_ 118 CellVoltage01 "CellVoltage01";
CM_ SG_ 118 SampleAgeMs "Maximum age of valid samples in this frozen scan at capture; saturates at 65535 ms.";
CM_ SG_ 118 SampleValidMask "Bit 0 corresponds to cell 01; bit 31 to cell 32. Clear bits mean unavailable readings and their encoded values must be ignored.";
CM_ SG_ 118 SnapshotId "Matches BPSFaultSnapshot SnapshotId.";
CM_ BO_ 119 "Latch once when BPS transitions from no active faults to any active fault, before opening contactors where possible. Send immediately, then every 1000 ms only while any BPS fault remains active. All three frames reuse the same frozen SnapshotId; never replace captured samples with post-trip zeros. Rearm after all faults clear. SnapshotId is a wrapping 16-bit sequence within a boot. The last completed scan available at fault detection is frozen, not acquired after shutdown. Scaling and offsets match BPSTemperatureData.";
CM_ SG_ 119 CellTemperature32 "CellTemperature32";
CM_ SG_ 119 CellTemperature31 "CellTemperature31";
CM_ SG_ 119 CellTemperature30 "CellTemperature30";
CM_ SG_ 119 CellTemperature29 "CellTemperature29";
CM_ SG_ 119 CellTemperature28 "CellTemperature28";
CM_ SG_ 119 CellTemperature27 "CellTemperature27";
CM_ SG_ 119 CellTemperature26 "CellTemperature26";
CM_ SG_ 119 CellTemperature25 "CellTemperature25";
CM_ SG_ 119 CellTemperature24 "CellTemperature24";
CM_ SG_ 119 CellTemperature23 "CellTemperature23";
CM_ SG_ 119 CellTemperature22 "CellTemperature22";
CM_ SG_ 119 CellTemperature21 "CellTemperature21";
CM_ SG_ 119 CellTemperature20 "CellTemperature20";
CM_ SG_ 119 CellTemperature19 "CellTemperature19";
CM_ SG_ 119 CellTemperature18 "CellTemperature18";
CM_ SG_ 119 CellTemperature17 "CellTemperature17";
CM_ SG_ 119 CellTemperature16 "CellTemperature16";
CM_ SG_ 119 CellTemperature15 "CellTemperature15";
CM_ SG_ 119 CellTemperature14 "CellTemperature14";
CM_ SG_ 119 CellTemperature13 "CellTemperature13";
CM_ SG_ 119 CellTemperature12 "CellTemperature12";
CM_ SG_ 119 CellTemperature11 "CellTemperature11";
CM_ SG_ 119 CellTemperature10 "CellTemperature10";
CM_ SG_ 119 CellTemperature09 "CellTemperature09";
CM_ SG_ 119 CellTemperature08 "CellTemperature08";
CM_ SG_ 119 CellTemperature07 "CellTemperature07";
CM_ SG_ 119 CellTemperature06 "CellTemperature06";
CM_ SG_ 119 CellTemperature05 "CellTemperature05";
CM_ SG_ 119 CellTemperature04 "CellTemperature04";
CM_ SG_ 119 CellTemperature03 "CellTemperature03";
CM_ SG_ 119 CellTemperature02 "CellTemperature02";
CM_ SG_ 119 CellTemperature01 "CellTemperature01";
CM_ SG_ 119 SampleAgeMs "Maximum age of valid samples in this frozen scan at capture; saturates at 65535 ms.";
CM_ SG_ 119 SampleValidMask "Bit 0 corresponds to cell 01; bit 31 to cell 32. Clear bits mean unavailable readings and their encoded values must be ignored.";
CM_ SG_ 119 SnapshotId "Matches BPSFaultSnapshot SnapshotId.";
BA_DEF_ SG_  "ValueTable" STRING ;
BA_DEF_ BO_  "LayoutPending" INT 0 1;
BA_DEF_ BO_  "ProtocolSource" STRING ;
BA_DEF_  "BusType" STRING ;
BA_DEF_  "DBName" STRING ;
BA_DEF_ SG_  "SystemSignalLongSymbol" STRING ;
BA_DEF_ BO_  "VFrameFormat" ENUM  "StandardCAN","ExtendedCAN","reserved","J1939PG","reserved","reserved","reserved","reserved","reserved","reserved","reserved","reserved","reserved","reserved","StandardCAN_FD","ExtendedCAN_FD";
BA_DEF_ BO_  "CANFD_BRS" ENUM  "0","1";
BA_DEF_ BO_  "GenMsgSendType" ENUM  "Cyclic","Triggered","None";
BA_DEF_ BO_  "GenMsgCycleTime" INT 0 65535;
BA_DEF_  "Baudrate" INT 1 10000000;
BA_DEF_  "DataBaudrate" INT 1 10000000;
BA_DEF_ BO_  "GenMsgSendCondition" STRING ;
BA_DEF_DEF_  "ValueTable" "";
BA_DEF_DEF_  "LayoutPending" 0;
BA_DEF_DEF_  "ProtocolSource" "";
BA_DEF_DEF_  "BusType" "CAN";
BA_DEF_DEF_  "DBName" "";
BA_DEF_DEF_  "SystemSignalLongSymbol" "";
BA_DEF_DEF_  "VFrameFormat" "StandardCAN";
BA_DEF_DEF_  "CANFD_BRS" "0";
BA_DEF_DEF_  "GenMsgSendType" "Cyclic";
BA_DEF_DEF_  "GenMsgCycleTime" 0;
BA_DEF_DEF_  "GenMsgSendCondition" "";
BA_ "BusType" "CAN FD";
BA_ "DBName" "CarCAN";
BA_ "Baudrate" 1000000;
BA_ "DataBaudrate" 1000000;
BA_ "ProtocolSource" BO_ 81 "2027 allocation draft";
BA_ "VFrameFormat" BO_ 81 14;
BA_ "GenMsgSendType" BO_ 81 1;
BA_ "ValueTable" SG_ 81 MPPTChargeScheme "NormalAdvanced";
BA_ "ValueTable" SG_ 81 Mode "NormalAdvanced";
BA_ "ProtocolSource" BO_ 82 "2027 allocation draft";
BA_ "VFrameFormat" BO_ 82 14;
BA_ "GenMsgSendType" BO_ 82 1;
BA_ "ValueTable" SG_ 82 Enable "EnableDisable";
BA_ "ProtocolSource" BO_ 83 "2027 allocation draft";
BA_ "VFrameFormat" BO_ 83 14;
BA_ "GenMsgSendType" BO_ 83 1;
BA_ "ValueTable" SG_ 83 CommandSource "MotorCommandSource";
BA_ "ProtocolSource" BO_ 84 "2027 allocation draft";
BA_ "VFrameFormat" BO_ 84 14;
BA_ "GenMsgSendType" BO_ 84 1;
BA_ "ProtocolSource" BO_ 96 "2027 allocation draft";
BA_ "VFrameFormat" BO_ 96 14;
BA_ "GenMsgCycleTime" BO_ 96 200;
BA_ "ValueTable" SG_ 96 MotorPrechargeRelay "OnOff";
BA_ "ValueTable" SG_ 96 MainPrechargeRelay "OnOff";
BA_ "ValueTable" SG_ 96 HVNegativeContactor "OnOff";
BA_ "ValueTable" SG_ 96 MotorContactor "OnOff";
BA_ "ValueTable" SG_ 96 HVPositiveContactor "OnOff";
BA_ "ValueTable" SG_ 96 RegenChargeOK "Permission";
BA_ "ValueTable" SG_ 96 ElconChargeOK "Permission";
BA_ "ValueTable" SG_ 96 MPPTSetMode "TPEEControlMode";
BA_ "ValueTable" SG_ 96 ChargeOK "Permission";
BA_ "ValueTable" SG_ 96 DriveOK "Permission";
BA_ "ValueTable" SG_ 96 Status "DeviceStatus";
BA_ "ValueTable" SG_ 96 WarningBPSFan "WarningState";
BA_ "ValueTable" SG_ 96 WarningBatteryFan2 "WarningState";
BA_ "ValueTable" SG_ 96 WarningBatteryFan1 "WarningState";
BA_ "ValueTable" SG_ 96 WarningDischargeOverTemperature "WarningState";
BA_ "ValueTable" SG_ 96 WarningChargeOverTemperature "WarningState";
BA_ "ValueTable" SG_ 96 WarningOverVoltage "WarningState";
BA_ "ValueTable" SG_ 96 WarningUnderVoltage "WarningState";
BA_ "ValueTable" SG_ 96 WarningSMBCommunication "WarningState";
BA_ "ValueTable" SG_ 96 FaultMotorPrechargeVoltage "FaultState";
BA_ "ValueTable" SG_ 96 FaultMainPrechargeVoltage "FaultState";
BA_ "ValueTable" SG_ 96 FaultMotorVoltage "FaultState";
BA_ "ValueTable" SG_ 96 FaultMainVoltage "FaultState";
BA_ "ValueTable" SG_ 96 FaultMotorPrechargeTimeout "FaultState";
BA_ "ValueTable" SG_ 96 FaultMainPrechargeTimeout "FaultState";
BA_ "ValueTable" SG_ 96 FaultChargerEstop "FaultState";
BA_ "ValueTable" SG_ 96 FaultBatteryEstop "FaultState";
BA_ "ValueTable" SG_ 96 FaultExternalEstop "FaultState";
BA_ "ValueTable" SG_ 96 FaultDriverEstop "FaultState";
BA_ "ValueTable" SG_ 96 FaultMotorPrechargeRelayMismatch "FaultState";
BA_ "ValueTable" SG_ 96 FaultMainPrechargeRelayMismatch "FaultState";
BA_ "ValueTable" SG_ 96 FaultHVNegativeContactorMismatch "FaultState";
BA_ "ValueTable" SG_ 96 FaultMotorContactorMismatch "FaultState";
BA_ "ValueTable" SG_ 96 FaultHVPositiveContactorMismatch "FaultState";
BA_ "ValueTable" SG_ 96 FaultDischargeOverCurrent "FaultState";
BA_ "ValueTable" SG_ 96 FaultChargeOverCurrent "FaultState";
BA_ "ValueTable" SG_ 96 FaultUnderVoltage "FaultState";
BA_ "ValueTable" SG_ 96 FaultOverVoltage "FaultState";
BA_ "ValueTable" SG_ 96 FaultOverTemperature "FaultState";
BA_ "ValueTable" SG_ 96 FaultSummary "BPSFaultSummary";
BA_ "ProtocolSource" BO_ 97 "2027 allocation draft";
BA_ "VFrameFormat" BO_ 97 14;
BA_ "GenMsgCycleTime" BO_ 97 100;
BA_ "ValueTable" SG_ 97 HandbrakePressureSwitch "OnOff";
BA_ "ValueTable" SG_ 97 FrontPressureSwitch "OnOff";
BA_ "ValueTable" SG_ 97 BrakeActive "OnOff";
BA_ "ValueTable" SG_ 97 WarningPressureSwitchMismatch "WarningState";
BA_ "ValueTable" SG_ 97 WarningRedundantAcceleratorDisco "WarningState";
BA_ "SystemSignalLongSymbol" SG_ 97 WarningRedundantAcceleratorDisco "WarningRedundantAcceleratorDisconnected";
BA_ "ValueTable" SG_ 97 WarningMainAcceleratorDisconnect "WarningState";
BA_ "SystemSignalLongSymbol" SG_ 97 WarningMainAcceleratorDisconnect "WarningMainAcceleratorDisconnected";
BA_ "ValueTable" SG_ 97 FaultNoAccelerator "FaultState";
BA_ "ValueTable" SG_ 97 Status "FaultState";
BA_ "ProtocolSource" BO_ 98 "2027 allocation draft";
BA_ "VFrameFormat" BO_ 98 14;
BA_ "GenMsgCycleTime" BO_ 98 100;
BA_ "ValueTable" SG_ 98 Headlights "OnOff";
BA_ "ValueTable" SG_ 98 PushToTalk "Pressed";
BA_ "ValueTable" SG_ 98 Horn "OnOff";
BA_ "ValueTable" SG_ 98 RegenActivate "OnOff";
BA_ "ValueTable" SG_ 98 RegenEnable "EnableDisable";
BA_ "ValueTable" SG_ 98 RightTurnSignal "OnOff";
BA_ "ValueTable" SG_ 98 LeftTurnSignal "OnOff";
BA_ "ValueTable" SG_ 98 Hazards "OnOff";
BA_ "ValueTable" SG_ 98 Gear "Gear";
BA_ "ValueTable" SG_ 98 IgnitionDrive "OnOff";
BA_ "ValueTable" SG_ 98 IgnitionCharge "OnOff";
BA_ "ValueTable" SG_ 98 IgnitionLV "OnOff";
BA_ "ProtocolSource" BO_ 99 "2027 allocation draft";
BA_ "VFrameFormat" BO_ 99 14;
BA_ "GenMsgCycleTime" BO_ 99 200;
BA_ "ValueTable" SG_ 99 MotorCommandSource "MotorCommandSource";
BA_ "ValueTable" SG_ 99 FSMGear "Gear";
BA_ "ValueTable" SG_ 99 FSMDriverRegenRequest "OnOff";
BA_ "ValueTable" SG_ 99 FSMDriverRegenEnable "EnableDisable";
BA_ "ValueTable" SG_ 99 FSMBPSRegenOK "Permission";
BA_ "ValueTable" SG_ 99 FSMBPSDriveOK "Permission";
BA_ "ValueTable" SG_ 99 FSMBrake "OnOff";
BA_ "ValueTable" SG_ 99 State "VCUState";
BA_ "ValueTable" SG_ 99 RegenEnabled "EnableDisable";
BA_ "ValueTable" SG_ 99 WarningMotorFan "WarningState";
BA_ "ValueTable" SG_ 99 WarningMotorControllerFan "WarningState";
BA_ "ValueTable" SG_ 99 WarningDirectionChangeLockout "WarningState";
BA_ "ValueTable" SG_ 99 WarningTipping "WarningState";
BA_ "ValueTable" SG_ 99 FaultPedalsWatchdog "FaultState";
BA_ "ValueTable" SG_ 99 FaultDriverInputWatchdog "FaultState";
BA_ "ValueTable" SG_ 99 FaultBPSWatchdog "FaultState";
BA_ "ValueTable" SG_ 99 FaultMotorControllerWatchdog "FaultState";
BA_ "ValueTable" SG_ 99 FaultPedals "FaultState";
BA_ "ValueTable" SG_ 99 FaultBPS "FaultState";
BA_ "ValueTable" SG_ 99 FaultMotor "FaultState";
BA_ "ValueTable" SG_ 99 Status "FaultState";
BA_ "ProtocolSource" BO_ 105 "2027 allocation draft";
BA_ "VFrameFormat" BO_ 105 14;
BA_ "GenMsgCycleTime" BO_ 105 500;
BA_ "ValueTable" SG_ 105 WarningOverCurrentTrip "WarningState";
BA_ "ValueTable" SG_ 105 WarningBlownFuse "WarningState";
BA_ "ProtocolSource" BO_ 106 "2027 allocation draft";
BA_ "VFrameFormat" BO_ 106 14;
BA_ "GenMsgCycleTime" BO_ 106 500;
BA_ "ValueTable" SG_ 106 DCDCEnabled "EnableDisable";
BA_ "ValueTable" SG_ 106 WarningBPSBlownFuse "WarningState";
BA_ "ValueTable" SG_ 106 WarningBPSOverCurrent "WarningState";
BA_ "ValueTable" SG_ 106 WarningNoDCDCOutput "WarningState";
BA_ "ProtocolSource" BO_ 112 "2027 allocation draft";
BA_ "VFrameFormat" BO_ 112 14;
BA_ "GenMsgCycleTime" BO_ 112 50;
BA_ "ProtocolSource" BO_ 113 "2027 allocation draft";
BA_ "VFrameFormat" BO_ 113 14;
BA_ "GenMsgCycleTime" BO_ 113 100;
BA_ "ProtocolSource" BO_ 114 "2027 allocation draft";
BA_ "VFrameFormat" BO_ 114 14;
BA_ "GenMsgCycleTime" BO_ 114 200;
BA_ "LayoutPending" BO_ 115 1;
BA_ "ProtocolSource" BO_ 115 "2027 allocation draft";
BA_ "VFrameFormat" BO_ 115 14;
BA_ "GenMsgCycleTime" BO_ 115 500;
BA_ "ProtocolSource" BO_ 116 "2027 allocation draft";
BA_ "VFrameFormat" BO_ 116 14;
BA_ "GenMsgCycleTime" BO_ 116 1000;
BA_ "ValueTable" SG_ 116 MPPTChargeScheme "NormalAdvanced";
BA_ "ValueTable" SG_ 116 Mode "NormalAdvanced";
BA_ "ProtocolSource" BO_ 120 "2027 allocation draft";
BA_ "VFrameFormat" BO_ 120 14;
BA_ "GenMsgCycleTime" BO_ 120 100;
BA_ "ValueTable" SG_ 120 ChannelEnabled14 "EnableDisable";
BA_ "ValueTable" SG_ 120 ChannelEnabled13 "EnableDisable";
BA_ "ValueTable" SG_ 120 ChannelEnabled12 "EnableDisable";
BA_ "ValueTable" SG_ 120 ChannelEnabled11 "EnableDisable";
BA_ "ValueTable" SG_ 120 ChannelEnabled10 "EnableDisable";
BA_ "ValueTable" SG_ 120 ChannelEnabled9 "EnableDisable";
BA_ "ValueTable" SG_ 120 ChannelEnabled8 "EnableDisable";
BA_ "ValueTable" SG_ 120 ChannelEnabled7 "EnableDisable";
BA_ "ValueTable" SG_ 120 ChannelEnabled6 "EnableDisable";
BA_ "ValueTable" SG_ 120 ChannelEnabled5 "EnableDisable";
BA_ "ValueTable" SG_ 120 ChannelEnabled4 "EnableDisable";
BA_ "ValueTable" SG_ 120 ChannelEnabled3 "EnableDisable";
BA_ "ValueTable" SG_ 120 ChannelEnabled2 "EnableDisable";
BA_ "ValueTable" SG_ 120 ChannelEnabled1 "EnableDisable";
BA_ "ValueTable" SG_ 120 ChannelOverCurrent14 "FaultState";
BA_ "ValueTable" SG_ 120 ChannelBlownFuse14 "FaultState";
BA_ "ValueTable" SG_ 120 ChannelOverCurrent13 "FaultState";
BA_ "ValueTable" SG_ 120 ChannelBlownFuse13 "FaultState";
BA_ "ValueTable" SG_ 120 ChannelOverCurrent12 "FaultState";
BA_ "ValueTable" SG_ 120 ChannelBlownFuse12 "FaultState";
BA_ "ValueTable" SG_ 120 ChannelOverCurrent11 "FaultState";
BA_ "ValueTable" SG_ 120 ChannelBlownFuse11 "FaultState";
BA_ "ValueTable" SG_ 120 ChannelOverCurrent10 "FaultState";
BA_ "ValueTable" SG_ 120 ChannelBlownFuse10 "FaultState";
BA_ "ValueTable" SG_ 120 ChannelOverCurrent9 "FaultState";
BA_ "ValueTable" SG_ 120 ChannelBlownFuse9 "FaultState";
BA_ "ValueTable" SG_ 120 ChannelOverCurrent8 "FaultState";
BA_ "ValueTable" SG_ 120 ChannelBlownFuse8 "FaultState";
BA_ "ValueTable" SG_ 120 ChannelOverCurrent7 "FaultState";
BA_ "ValueTable" SG_ 120 ChannelBlownFuse7 "FaultState";
BA_ "ValueTable" SG_ 120 ChannelOverCurrent6 "FaultState";
BA_ "ValueTable" SG_ 120 ChannelBlownFuse6 "FaultState";
BA_ "ValueTable" SG_ 120 ChannelOverCurrent5 "FaultState";
BA_ "ValueTable" SG_ 120 ChannelBlownFuse5 "FaultState";
BA_ "ValueTable" SG_ 120 ChannelOverCurrent4 "FaultState";
BA_ "ValueTable" SG_ 120 ChannelBlownFuse4 "FaultState";
BA_ "ValueTable" SG_ 120 ChannelOverCurrent3 "FaultState";
BA_ "ValueTable" SG_ 120 ChannelBlownFuse3 "FaultState";
BA_ "ValueTable" SG_ 120 ChannelOverCurrent2 "FaultState";
BA_ "ValueTable" SG_ 120 ChannelBlownFuse2 "FaultState";
BA_ "ValueTable" SG_ 120 ChannelOverCurrent1 "FaultState";
BA_ "ValueTable" SG_ 120 ChannelBlownFuse1 "FaultState";
BA_ "ProtocolSource" BO_ 121 "2027 allocation draft";
BA_ "VFrameFormat" BO_ 121 14;
BA_ "GenMsgCycleTime" BO_ 121 500;
BA_ "ValueTable" SG_ 121 SweepingActive "OnOff";
BA_ "ValueTable" SG_ 121 MPPTSetMode "TPEEControlMode";
BA_ "ValueTable" SG_ 121 WarningFan "WarningState";
BA_ "ValueTable" SG_ 121 WarningMPPTCWatchdog "WarningState";
BA_ "ValueTable" SG_ 121 WarningMPPTBWatchdog "WarningState";
BA_ "ValueTable" SG_ 121 WarningMPPTAWatchdog "WarningState";
BA_ "ValueTable" SG_ 121 WarningBPSWatchdog "WarningState";
BA_ "ProtocolSource" BO_ 130 "2027 allocation draft";
BA_ "VFrameFormat" BO_ 130 14;
BA_ "GenMsgCycleTime" BO_ 130 500;
BA_ "ValueTable" SG_ 130 DriverCameraConnected "Connection";
BA_ "ValueTable" SG_ 130 GPSConnected "Connection";
BA_ "ValueTable" SG_ 130 InternetConnected "Connection";
BA_ "ValueTable" SG_ 130 CellularConnected "Connection";
BA_ "ValueTable" SG_ 130 WarningRouterDisconnected "WarningState";
BA_ "ValueTable" SG_ 130 WarningRearCameraDisconnected "WarningState";
BA_ "ValueTable" SG_ 130 WarningDisplayDisconnected "WarningState";
BA_ "ValueTable" SG_ 130 WarningOverTemperature "WarningState";
BA_ "ValueTable" SG_ 130 WarningTemperature "WarningState";
BA_ "ProtocolSource" BO_ 117 "2027 allocation draft";
BA_ "VFrameFormat" BO_ 117 14;
BA_ "GenMsgCycleTime" BO_ 117 1000;
BA_ "GenMsgSendCondition" BO_ 117 "AnyBPSFaultActive && FaultSnapshotValid";
BA_ "ValueTable" SG_ 117 CurrentValid "Validity";
BA_ "ValueTable" SG_ 117 FaultMotorPrechargeVoltage "FaultState";
BA_ "ValueTable" SG_ 117 FaultMainPrechargeVoltage "FaultState";
BA_ "ValueTable" SG_ 117 FaultMotorVoltage "FaultState";
BA_ "ValueTable" SG_ 117 FaultMainVoltage "FaultState";
BA_ "ValueTable" SG_ 117 FaultMotorPrechargeTimeout "FaultState";
BA_ "ValueTable" SG_ 117 FaultMainPrechargeTimeout "FaultState";
BA_ "ValueTable" SG_ 117 FaultChargerEstop "FaultState";
BA_ "ValueTable" SG_ 117 FaultBatteryEstop "FaultState";
BA_ "ValueTable" SG_ 117 FaultExternalEstop "FaultState";
BA_ "ValueTable" SG_ 117 FaultDriverEstop "FaultState";
BA_ "ValueTable" SG_ 117 FaultMotorPrechargeRelayMismatch "FaultState";
BA_ "ValueTable" SG_ 117 FaultMainPrechargeRelayMismatch "FaultState";
BA_ "ValueTable" SG_ 117 FaultHVNegativeContactorMismatch "FaultState";
BA_ "ValueTable" SG_ 117 FaultMotorContactorMismatch "FaultState";
BA_ "ValueTable" SG_ 117 FaultHVPositiveContactorMismatch "FaultState";
BA_ "ValueTable" SG_ 117 FaultDischargeOverCurrent "FaultState";
BA_ "ValueTable" SG_ 117 FaultChargeOverCurrent "FaultState";
BA_ "ValueTable" SG_ 117 FaultUnderVoltage "FaultState";
BA_ "ValueTable" SG_ 117 FaultOverVoltage "FaultState";
BA_ "ValueTable" SG_ 117 FaultOverTemperature "FaultState";
BA_ "ValueTable" SG_ 117 FaultSummary "BPSFaultSummary";
BA_ "ProtocolSource" BO_ 118 "2027 allocation draft";
BA_ "VFrameFormat" BO_ 118 14;
BA_ "GenMsgCycleTime" BO_ 118 1000;
BA_ "GenMsgSendCondition" BO_ 118 "AnyBPSFaultActive && FaultSnapshotValid";
BA_ "ProtocolSource" BO_ 119 "2027 allocation draft";
BA_ "VFrameFormat" BO_ 119 14;
BA_ "GenMsgCycleTime" BO_ 119 1000;
BA_ "GenMsgSendCondition" BO_ 119 "AnyBPSFaultActive && FaultSnapshotValid";
VAL_ 81 MPPTChargeScheme 0 "Normal" 1 "Advanced" ;
VAL_ 81 Mode 0 "Normal" 1 "Advanced" ;
VAL_ 82 Enable 0 "Disabled" 1 "Enabled" ;
VAL_ 83 CommandSource 0 "VCU" 1 "External" ;
VAL_ 96 MotorPrechargeRelay 0 "Off" 1 "On" ;
VAL_ 96 MainPrechargeRelay 0 "Off" 1 "On" ;
VAL_ 96 HVNegativeContactor 0 "Off" 1 "On" ;
VAL_ 96 MotorContactor 0 "Off" 1 "On" ;
VAL_ 96 HVPositiveContactor 0 "Off" 1 "On" ;
VAL_ 96 RegenChargeOK 0 "NotAllowed" 1 "Allowed" ;
VAL_ 96 ElconChargeOK 0 "NotAllowed" 1 "Allowed" ;
VAL_ 96 MPPTSetMode 0 "Disabled" 1 "PerturbAndObserve" 2 "ConstantInputVoltage" ;
VAL_ 96 ChargeOK 0 "NotAllowed" 1 "Allowed" ;
VAL_ 96 DriveOK 0 "NotAllowed" 1 "Allowed" ;
VAL_ 96 Status 0 "OK" 1 "Fault" 2 "Waiting" ;
VAL_ 96 WarningBPSFan 0 "NoWarning" 1 "Warning" ;
VAL_ 96 WarningBatteryFan2 0 "NoWarning" 1 "Warning" ;
VAL_ 96 WarningBatteryFan1 0 "NoWarning" 1 "Warning" ;
VAL_ 96 WarningDischargeOverTemperature 0 "NoWarning" 1 "Warning" ;
VAL_ 96 WarningChargeOverTemperature 0 "NoWarning" 1 "Warning" ;
VAL_ 96 WarningOverVoltage 0 "NoWarning" 1 "Warning" ;
VAL_ 96 WarningUnderVoltage 0 "NoWarning" 1 "Warning" ;
VAL_ 96 WarningSMBCommunication 0 "NoWarning" 1 "Warning" ;
VAL_ 96 FaultMotorPrechargeVoltage 0 "OK" 1 "Fault" ;
VAL_ 96 FaultMainPrechargeVoltage 0 "OK" 1 "Fault" ;
VAL_ 96 FaultMotorVoltage 0 "OK" 1 "Fault" ;
VAL_ 96 FaultMainVoltage 0 "OK" 1 "Fault" ;
VAL_ 96 FaultMotorPrechargeTimeout 0 "OK" 1 "Fault" ;
VAL_ 96 FaultMainPrechargeTimeout 0 "OK" 1 "Fault" ;
VAL_ 96 FaultChargerEstop 0 "OK" 1 "Fault" ;
VAL_ 96 FaultBatteryEstop 0 "OK" 1 "Fault" ;
VAL_ 96 FaultExternalEstop 0 "OK" 1 "Fault" ;
VAL_ 96 FaultDriverEstop 0 "OK" 1 "Fault" ;
VAL_ 96 FaultMotorPrechargeRelayMismatch 0 "OK" 1 "Fault" ;
VAL_ 96 FaultMainPrechargeRelayMismatch 0 "OK" 1 "Fault" ;
VAL_ 96 FaultHVNegativeContactorMismatch 0 "OK" 1 "Fault" ;
VAL_ 96 FaultMotorContactorMismatch 0 "OK" 1 "Fault" ;
VAL_ 96 FaultHVPositiveContactorMismatch 0 "OK" 1 "Fault" ;
VAL_ 96 FaultDischargeOverCurrent 0 "OK" 1 "Fault" ;
VAL_ 96 FaultChargeOverCurrent 0 "OK" 1 "Fault" ;
VAL_ 96 FaultUnderVoltage 0 "OK" 1 "Fault" ;
VAL_ 96 FaultOverVoltage 0 "OK" 1 "Fault" ;
VAL_ 96 FaultOverTemperature 0 "OK" 1 "Fault" ;
VAL_ 96 FaultSummary 0 "OK" 1 "SetpointFault" 2 "EmergencyStop" 3 "ContactorRelayFault" 4 "PrechargeFault" 5 "SMBFault" ;
VAL_ 97 HandbrakePressureSwitch 0 "Off" 1 "On" ;
VAL_ 97 FrontPressureSwitch 0 "Off" 1 "On" ;
VAL_ 97 BrakeActive 0 "Off" 1 "On" ;
VAL_ 97 WarningPressureSwitchMismatch 0 "NoWarning" 1 "Warning" ;
VAL_ 97 WarningRedundantAcceleratorDisco 0 "NoWarning" 1 "Warning" ;
VAL_ 97 WarningMainAcceleratorDisconnect 0 "NoWarning" 1 "Warning" ;
VAL_ 97 FaultNoAccelerator 0 "OK" 1 "Fault" ;
VAL_ 97 Status 0 "OK" 1 "Fault" ;
VAL_ 98 Headlights 0 "Off" 1 "On" ;
VAL_ 98 PushToTalk 0 "NotPressed" 1 "Pressed" ;
VAL_ 98 Horn 0 "Off" 1 "On" ;
VAL_ 98 RegenActivate 0 "Off" 1 "On" ;
VAL_ 98 RegenEnable 0 "Disabled" 1 "Enabled" ;
VAL_ 98 RightTurnSignal 0 "Off" 1 "On" ;
VAL_ 98 LeftTurnSignal 0 "Off" 1 "On" ;
VAL_ 98 Hazards 0 "Off" 1 "On" ;
VAL_ 98 Gear 0 "Neutral" 1 "Forward" 2 "Reverse" 3 "Invalid" ;
VAL_ 98 IgnitionDrive 0 "Off" 1 "On" ;
VAL_ 98 IgnitionCharge 0 "Off" 1 "On" ;
VAL_ 98 IgnitionLV 0 "Off" 1 "On" ;
VAL_ 99 MotorCommandSource 0 "VCU" 1 "External" ;
VAL_ 99 FSMGear 0 "Neutral" 1 "Forward" 2 "Reverse" 3 "Invalid" ;
VAL_ 99 FSMDriverRegenRequest 0 "Off" 1 "On" ;
VAL_ 99 FSMDriverRegenEnable 0 "Disabled" 1 "Enabled" ;
VAL_ 99 FSMBPSRegenOK 0 "NotAllowed" 1 "Allowed" ;
VAL_ 99 FSMBPSDriveOK 0 "NotAllowed" 1 "Allowed" ;
VAL_ 99 FSMBrake 0 "Off" 1 "On" ;
VAL_ 99 State 0 "Init" 1 "ForwardDrive" 2 "NeutralDrive" 3 "ReverseDrive" 4 "Regen" 5 "CruiseControl" 6 "Disabled" 7 "VehicleNotReady" ;
VAL_ 99 RegenEnabled 0 "Disabled" 1 "Enabled" ;
VAL_ 99 WarningMotorFan 0 "NoWarning" 1 "Warning" ;
VAL_ 99 WarningMotorControllerFan 0 "NoWarning" 1 "Warning" ;
VAL_ 99 WarningDirectionChangeLockout 0 "NoWarning" 1 "Warning" ;
VAL_ 99 WarningTipping 0 "NoWarning" 1 "Warning" ;
VAL_ 99 FaultPedalsWatchdog 0 "OK" 1 "Fault" ;
VAL_ 99 FaultDriverInputWatchdog 0 "OK" 1 "Fault" ;
VAL_ 99 FaultBPSWatchdog 0 "OK" 1 "Fault" ;
VAL_ 99 FaultMotorControllerWatchdog 0 "OK" 1 "Fault" ;
VAL_ 99 FaultPedals 0 "OK" 1 "Fault" ;
VAL_ 99 FaultBPS 0 "OK" 1 "Fault" ;
VAL_ 99 FaultMotor 0 "OK" 1 "Fault" ;
VAL_ 99 Status 0 "OK" 1 "Fault" ;
VAL_ 105 WarningOverCurrentTrip 0 "NoWarning" 1 "Warning" ;
VAL_ 105 WarningBlownFuse 0 "NoWarning" 1 "Warning" ;
VAL_ 106 DCDCEnabled 0 "Disabled" 1 "Enabled" ;
VAL_ 106 WarningBPSBlownFuse 0 "NoWarning" 1 "Warning" ;
VAL_ 106 WarningBPSOverCurrent 0 "NoWarning" 1 "Warning" ;
VAL_ 106 WarningNoDCDCOutput 0 "NoWarning" 1 "Warning" ;
VAL_ 116 MPPTChargeScheme 0 "Normal" 1 "Advanced" ;
VAL_ 116 Mode 0 "Normal" 1 "Advanced" ;
VAL_ 120 ChannelEnabled14 0 "Disabled" 1 "Enabled" ;
VAL_ 120 ChannelEnabled13 0 "Disabled" 1 "Enabled" ;
VAL_ 120 ChannelEnabled12 0 "Disabled" 1 "Enabled" ;
VAL_ 120 ChannelEnabled11 0 "Disabled" 1 "Enabled" ;
VAL_ 120 ChannelEnabled10 0 "Disabled" 1 "Enabled" ;
VAL_ 120 ChannelEnabled9 0 "Disabled" 1 "Enabled" ;
VAL_ 120 ChannelEnabled8 0 "Disabled" 1 "Enabled" ;
VAL_ 120 ChannelEnabled7 0 "Disabled" 1 "Enabled" ;
VAL_ 120 ChannelEnabled6 0 "Disabled" 1 "Enabled" ;
VAL_ 120 ChannelEnabled5 0 "Disabled" 1 "Enabled" ;
VAL_ 120 ChannelEnabled4 0 "Disabled" 1 "Enabled" ;
VAL_ 120 ChannelEnabled3 0 "Disabled" 1 "Enabled" ;
VAL_ 120 ChannelEnabled2 0 "Disabled" 1 "Enabled" ;
VAL_ 120 ChannelEnabled1 0 "Disabled" 1 "Enabled" ;
VAL_ 120 ChannelOverCurrent14 0 "OK" 1 "Fault" ;
VAL_ 120 ChannelBlownFuse14 0 "OK" 1 "Fault" ;
VAL_ 120 ChannelOverCurrent13 0 "OK" 1 "Fault" ;
VAL_ 120 ChannelBlownFuse13 0 "OK" 1 "Fault" ;
VAL_ 120 ChannelOverCurrent12 0 "OK" 1 "Fault" ;
VAL_ 120 ChannelBlownFuse12 0 "OK" 1 "Fault" ;
VAL_ 120 ChannelOverCurrent11 0 "OK" 1 "Fault" ;
VAL_ 120 ChannelBlownFuse11 0 "OK" 1 "Fault" ;
VAL_ 120 ChannelOverCurrent10 0 "OK" 1 "Fault" ;
VAL_ 120 ChannelBlownFuse10 0 "OK" 1 "Fault" ;
VAL_ 120 ChannelOverCurrent9 0 "OK" 1 "Fault" ;
VAL_ 120 ChannelBlownFuse9 0 "OK" 1 "Fault" ;
VAL_ 120 ChannelOverCurrent8 0 "OK" 1 "Fault" ;
VAL_ 120 ChannelBlownFuse8 0 "OK" 1 "Fault" ;
VAL_ 120 ChannelOverCurrent7 0 "OK" 1 "Fault" ;
VAL_ 120 ChannelBlownFuse7 0 "OK" 1 "Fault" ;
VAL_ 120 ChannelOverCurrent6 0 "OK" 1 "Fault" ;
VAL_ 120 ChannelBlownFuse6 0 "OK" 1 "Fault" ;
VAL_ 120 ChannelOverCurrent5 0 "OK" 1 "Fault" ;
VAL_ 120 ChannelBlownFuse5 0 "OK" 1 "Fault" ;
VAL_ 120 ChannelOverCurrent4 0 "OK" 1 "Fault" ;
VAL_ 120 ChannelBlownFuse4 0 "OK" 1 "Fault" ;
VAL_ 120 ChannelOverCurrent3 0 "OK" 1 "Fault" ;
VAL_ 120 ChannelBlownFuse3 0 "OK" 1 "Fault" ;
VAL_ 120 ChannelOverCurrent2 0 "OK" 1 "Fault" ;
VAL_ 120 ChannelBlownFuse2 0 "OK" 1 "Fault" ;
VAL_ 120 ChannelOverCurrent1 0 "OK" 1 "Fault" ;
VAL_ 120 ChannelBlownFuse1 0 "OK" 1 "Fault" ;
VAL_ 121 SweepingActive 0 "Off" 1 "On" ;
VAL_ 121 MPPTSetMode 0 "Disabled" 1 "PerturbAndObserve" 2 "ConstantInputVoltage" ;
VAL_ 121 WarningFan 0 "NoWarning" 1 "Warning" ;
VAL_ 121 WarningMPPTCWatchdog 0 "NoWarning" 1 "Warning" ;
VAL_ 121 WarningMPPTBWatchdog 0 "NoWarning" 1 "Warning" ;
VAL_ 121 WarningMPPTAWatchdog 0 "NoWarning" 1 "Warning" ;
VAL_ 121 WarningBPSWatchdog 0 "NoWarning" 1 "Warning" ;
VAL_ 130 DriverCameraConnected 0 "Disconnected" 1 "Connected" ;
VAL_ 130 GPSConnected 0 "Disconnected" 1 "Connected" ;
VAL_ 130 InternetConnected 0 "Disconnected" 1 "Connected" ;
VAL_ 130 CellularConnected 0 "Disconnected" 1 "Connected" ;
VAL_ 130 WarningRouterDisconnected 0 "NoWarning" 1 "Warning" ;
VAL_ 130 WarningRearCameraDisconnected 0 "NoWarning" 1 "Warning" ;
VAL_ 130 WarningDisplayDisconnected 0 "NoWarning" 1 "Warning" ;
VAL_ 130 WarningOverTemperature 0 "NoWarning" 1 "Warning" ;
VAL_ 130 WarningTemperature 0 "NoWarning" 1 "Warning" ;
VAL_ 117 CurrentValid 1 "Valid" 0 "Invalid" ;
VAL_ 117 FaultMotorPrechargeVoltage 0 "OK" 1 "Fault" ;
VAL_ 117 FaultMainPrechargeVoltage 0 "OK" 1 "Fault" ;
VAL_ 117 FaultMotorVoltage 0 "OK" 1 "Fault" ;
VAL_ 117 FaultMainVoltage 0 "OK" 1 "Fault" ;
VAL_ 117 FaultMotorPrechargeTimeout 0 "OK" 1 "Fault" ;
VAL_ 117 FaultMainPrechargeTimeout 0 "OK" 1 "Fault" ;
VAL_ 117 FaultChargerEstop 0 "OK" 1 "Fault" ;
VAL_ 117 FaultBatteryEstop 0 "OK" 1 "Fault" ;
VAL_ 117 FaultExternalEstop 0 "OK" 1 "Fault" ;
VAL_ 117 FaultDriverEstop 0 "OK" 1 "Fault" ;
VAL_ 117 FaultMotorPrechargeRelayMismatch 0 "OK" 1 "Fault" ;
VAL_ 117 FaultMainPrechargeRelayMismatch 0 "OK" 1 "Fault" ;
VAL_ 117 FaultHVNegativeContactorMismatch 0 "OK" 1 "Fault" ;
VAL_ 117 FaultMotorContactorMismatch 0 "OK" 1 "Fault" ;
VAL_ 117 FaultHVPositiveContactorMismatch 0 "OK" 1 "Fault" ;
VAL_ 117 FaultDischargeOverCurrent 0 "OK" 1 "Fault" ;
VAL_ 117 FaultChargeOverCurrent 0 "OK" 1 "Fault" ;
VAL_ 117 FaultUnderVoltage 0 "OK" 1 "Fault" ;
VAL_ 117 FaultOverVoltage 0 "OK" 1 "Fault" ;
VAL_ 117 FaultOverTemperature 0 "OK" 1 "Fault" ;
VAL_ 117 FaultSummary 0 "OK" 1 "SetpointFault" 2 "EmergencyStop" 3 "ContactorRelayFault" 4 "PrechargeFault" 5 "SMBFault" ;
